VERSION ""

NS_ :

BS_:

BU_: PDCF VDC821 VDC397 HAD3971 PDCM CSC PDCR

BO_ 192 ABS_1: 32 PDCF
 SG_ Checksum_ABS_1 : 0|8@1+ (1,0) [0|255] ""  VDC821,VDC397,HAD3971,PDCM,PDCR
 SG_ WheelSpeed_FL : 8|15@1+ (0.01,0) [0|327.67] "km/h"  VDC821,VDC397,HAD3971,PDCR
 SG_ WheelSpeed_FR : 24|15@1+ (0.01,0) [0|327.67] "km/h"  VDC821,VDC397,HAD3971,PDCR
 SG_ WheelSpeed_RL : 40|15@1+ (0.01,0) [0|327.67] "km/h"  VDC821,VDC397,HAD3971,PDCR
 SG_ WheelSpeed_RR : 56|15@1+ (0.01,0) [0|327.67] "km/h"  VDC821,VDC397,HAD3971,PDCR
 SG_ WheelPulse_FL : 72|8@1+ (1,0) [0|255] ""  VDC821,VDC397,HAD3971,PDCR
 SG_ WheelPulse_FR : 80|8@1+ (1,0) [0|255] ""  VDC821,VDC397,HAD3971,PDCR
 SG_ WheelPulse_RL : 88|8@1+ (1,0) [0|255] ""  VDC821,VDC397,HAD3971,PDCR
 SG_ WheelPulse_RR : 96|8@1+ (1,0) [0|255] ""  VDC821,VDC397,HAD3971,PDCR
 SG_ WheelSpeedDirection_FL : 104|2@1+ (1,0) [0|3] ""  VDC821,VDC397,PDCR
 SG_ WheelSpeedDirection_FR : 106|2@1+ (1,0) [0|3] ""  VDC821,VDC397,PDCR
 SG_ WheelSpeedDirection_RL : 108|2@1+ (1,0) [0|3] ""  VDC821,VDC397,PDCR
 SG_ WheelSpeedDirection_RR : 110|2@1+ (1,0) [0|3] ""  VDC821,VDC397,PDCR
 SG_ WheelSpeedDirection_FL_Q : 112|1@1+ (1,0) [0|1] ""  VDC821,VDC397,PDCR
 SG_ WheelSpeedDirection_FR_Q : 113|1@1+ (1,0) [0|1] ""  VDC821,VDC397,PDCR
 SG_ WheelSpeedDirection_RL_Q : 114|1@1+ (1,0) [0|1] ""  VDC821,VDC397,PDCR
 SG_ WheelSpeedDirection_RR_Q : 115|1@1+ (1,0) [0|1] ""  VDC821,VDC397,PDCR
 SG_ VehicleSpeed : 120|15@1+ (0.01,0) [0|327.67] "km/h"  VDC821,VDC397,HAD3971,PDCM,PDCR
 SG_ VehiclSpeed_Q : 135|1@1+ (1,0) [0|1] ""  VDC821,VDC397,HAD3971,PDCR
 SG_ DrivingDirection : 136|2@1+ (1,0) [0|3] ""  VDC821,VDC397,HAD3971
 SG_ DrivingDirection_Q : 138|1@1+ (1,0) [0|1] ""  VDC821,VDC397,HAD3971
 SG_ BrakeTorqueOnWheels : 152|12@1+ (2,0) [0|8190] "Nm"  VDC821,VDC397
 SG_ EstimatedWheelPressure_FL : 168|14@1+ (0.03125,-50) [-50|450] "bar"  VDC821,VDC397,PDCR
 SG_ EstimatedWheelPressure_FR : 184|14@1+ (0.03125,-50) [-50|450] "bar"  VDC821,VDC397,PDCR
 SG_ EstimatedWheelPressure_RL : 200|14@1+ (0.03125,-50) [-50|450] "bar"  VDC821,VDC397,PDCR
 SG_ EstimatedWheelPressure_RR : 216|14@1+ (0.03125,-50) [-50|450] "bar"  VDC821,VDC397,PDCR
 SG_ LiveCounter_ABS_1 : 252|4@1+ (1,0) [0|15] ""  VDC821,VDC397,HAD3971,PDCM,PDCR

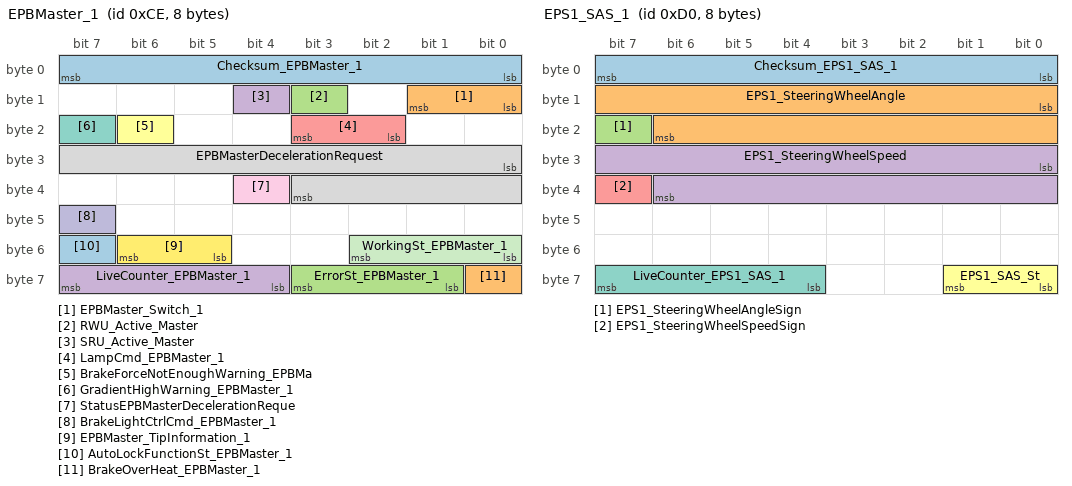
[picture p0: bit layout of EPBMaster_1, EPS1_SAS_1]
BO_ 206 EPBMaster_1: 8 PDCF
 SG_ Checksum_EPBMaster_1 : 0|8@1+ (1,0) [0|255] ""  VDC821,VDC397,HAD3971,PDCM,CSC
 SG_ EPBMaster_Switch_1 : 8|2@1+ (1,0) [0|3] ""  PDCM
 SG_ RWU_Active_Master : 11|1@1+ (1,0) [0|1] ""  PDCM
 SG_ SRU_Active_Master : 12|1@1+ (1,0) [0|1] ""  PDCM
 SG_ LampCmd_EPBMaster_1 : 18|2@1+ (1,0) [0|3] ""  PDCM,CSC
 SG_ BrakeForceNotEnoughWarning_EPBMa : 22|1@1+ (1,0) [0|1] ""  PDCM
 SG_ GradientHighWarning_EPBMaster_1 : 23|1@1+ (1,0) [0|1] ""  PDCM
 SG_ EPBMasterDecelerationRequest : 24|12@1+ (0.01,-20.47) [-20.47|20.48] "m/s2"  PDCM
 SG_ StatusEPBMasterDecelerationReque : 36|1@1+ (1,0) [0|1] ""  PDCM
 SG_ BrakeLightCtrlCmd_EPBMaster_1 : 47|1@1+ (1,0) [0|1] ""  VDC821,VDC397,PDCM
 SG_ WorkingSt_EPBMaster_1 : 48|3@1+ (1,0) [0|7] ""  VDC821,VDC397,HAD3971,PDCM,PDCR,CSC
 SG_ EPBMaster_TipInformation_1 : 53|2@1+ (1,0) [0|3] ""  PDCM
 SG_ AutoLockFunctionSt_EPBMaster_1 : 55|1@1+ (1,0) [0|1] ""  PDCM
 SG_ BrakeOverHeat_EPBMaster_1 : 56|1@1+ (1,0) [0|1] ""  PDCM
 SG_ ErrorSt_EPBMaster_1 : 57|3@1+ (1,0) [0|7] ""  VDC821,VDC397,HAD3971,PDCM
 SG_ LiveCounter_EPBMaster_1 : 60|4@1+ (1,0) [0|15] ""  VDC821,VDC397,PDCM,CSC

BO_ 208 EPS1_SAS_1: 8 PDCF
 SG_ Checksum_EPS1_SAS_1 : 0|8@1+ (1,0) [0|255] ""  VDC821,VDC397,HAD3971,PDCM,PDCR
 SG_ EPS1_SteeringWheelAngle : 8|15@1+ (0.04375,0) [0|1433.55625] "°„"  VDC821,VDC397,HAD3971,PDCM,PDCR
 SG_ EPS1_SteeringWheelAngleSign : 23|1@1+ (1,0) [0|1] ""  VDC821,VDC397,HAD3971,PDCR
 SG_ EPS1_SteeringWheelSpeed : 24|15@1+ (0.04375,0) [0|1433.55625] "°„/s"  VDC821,VDC397,HAD3971,PDCR
 SG_ EPS1_SteeringWheelSpeedSign : 39|1@1+ (1,0) [0|1] ""  VDC821,VDC397,HAD3971,PDCR
 SG_ EPS1_SAS_St : 56|2@1+ (1,0) [0|3] ""  VDC821,VDC397,HAD3971,PDCR
 SG_ LiveCounter_EPS1_SAS_1 : 60|4@1+ (1,0) [0|15] ""  VDC821,VDC397,HAD3971,PDCM,PDCR

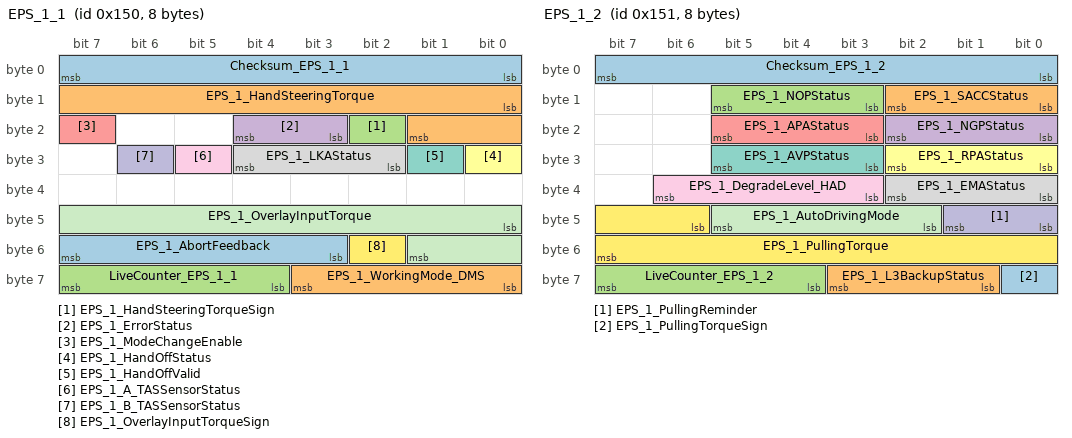
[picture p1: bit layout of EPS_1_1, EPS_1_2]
BO_ 336 EPS_1_1: 8 PDCF
 SG_ Checksum_EPS_1_1 : 0|8@1+ (1,0) [0|255] ""  VDC821,VDC397,HAD3971
 SG_ EPS_1_HandSteeringTorque : 8|10@1+ (0.01,0) [0|10] "Nm"  VDC821,VDC397,HAD3971
 SG_ EPS_1_HandSteeringTorqueSign : 18|1@1+ (1,0) [0|1] ""  VDC821,VDC397,HAD3971
 SG_ EPS_1_ErrorStatus : 19|2@1+ (1,0) [0|3] ""  VDC821,VDC397,HAD3971
 SG_ EPS_1_ModeChangeEnable : 23|1@1+ (1,0) [0|1] ""  VDC821,VDC397
 SG_ EPS_1_HandOffStatus : 24|1@1+ (1,0) [0|1] ""  VDC821,VDC397,HAD3971
 SG_ EPS_1_HandOffValid : 25|1@1+ (1,0) [0|1] ""  VDC821,VDC397,HAD3971
 SG_ EPS_1_LKAStatus : 26|3@1+ (1,0) [0|7] ""  VDC821,VDC397
 SG_ EPS_1_A_TASSensorStatus : 29|1@1+ (1,0) [0|1] ""  VDC821,VDC397
 SG_ EPS_1_B_TASSensorStatus : 30|1@1+ (1,0) [0|1] ""  VDC821,VDC397
 SG_ EPS_1_OverlayInputTorque : 40|10@1+ (0.01,0) [0|10] "Nm"  VDC821,VDC397,HAD3971
 SG_ EPS_1_OverlayInputTorqueSign : 50|1@1+ (1,0) [0|1] ""  VDC821,VDC397,HAD3971
 SG_ EPS_1_AbortFeedback : 51|5@1+ (1,0) [0|31] ""  VDC821,VDC397,HAD3971
 SG_ EPS_1_WorkingMode_DMS : 56|4@1+ (1,0) [0|15] ""  VDC821,VDC397
 SG_ LiveCounter_EPS_1_1 : 60|4@1+ (1,0) [0|15] "Pulse"  VDC821,VDC397

BO_ 337 EPS_1_2: 8 PDCF
 SG_ Checksum_EPS_1_2 : 0|8@1+ (1,0) [0|255] ""  VDC821,VDC397,HAD3971
 SG_ EPS_1_SACCStatus : 8|3@1+ (1,0) [0|7] ""  VDC821,VDC397
 SG_ EPS_1_NOPStatus : 11|3@1+ (1,0) [0|7] ""  VDC821,VDC397,HAD3971
 SG_ EPS_1_NGPStatus : 16|3@1+ (1,0) [0|7] ""  VDC821,VDC397
 SG_ EPS_1_APAStatus : 19|3@1+ (1,0) [0|7] ""  VDC821,VDC397
 SG_ EPS_1_RPAStatus : 24|3@1+ (1,0) [0|7] ""  VDC821,VDC397
 SG_ EPS_1_AVPStatus : 27|3@1+ (1,0) [0|7] ""  VDC821,VDC397
 SG_ EPS_1_EMAStatus : 32|3@1+ (1,0) [0|7] ""  VDC821,VDC397
 SG_ EPS_1_DegradeLevel_HAD : 35|4@1+ (1,0) [0|15] ""  VDC821,VDC397,HAD3971
 SG_ EPS_1_PullingReminder : 40|2@1+ (1,0) [0|3] ""  VDC821,VDC397,HAD3971
 SG_ EPS_1_AutoDrivingMode : 42|4@1+ (1,0) [0|15] ""  VDC821,VDC397,HAD3971
 SG_ EPS_1_PullingTorque : 46|10@1+ (0.01,0) [0|10] "Nm"  VDC821,VDC397,HAD3971
 SG_ EPS_1_PullingTorqueSign : 56|1@1+ (1,0) [0|1] ""  VDC821,VDC397,HAD3971
 SG_ EPS_1_L3BackupStatus : 57|3@1+ (1,0) [0|7] ""  VDC821,VDC397
 SG_ LiveCounter_EPS_1_2 : 60|4@1+ (1,0) [0|15] ""  VDC821,VDC397,HAD3971

BO_ 195 ESC_1_W: 32 PDCF
 SG_ Checksum_ESC_1_W : 0|8@1+ (1,0) [0|255] ""  VDC821,VDC397,PDCR
 SG_ TorqueReductionFast_TCS_FrontWhe : 24|13@1+ (1,0) [0|8000] "Nm"  VDC821,VDC397
 SG_ TorqueIncrease_MSR_FrontWheel : 40|14@1+ (1,-8000) [-8000|8000] "Nm"  VDC821,VDC397
 SG_ TorqueReductionFast_TCS_RearWhee : 72|13@1+ (1,0) [0|8000] "Nm"  VDC821,VDC397
 SG_ TorqueIncrease_MSR_RearWheel : 88|14@1+ (1,-8000) [-8000|8000] "Nm"  VDC821,VDC397
 SG_ ESC_RegenerationTorqueRequest : 104|13@1+ (1,-8000) [-8000|0] "Nm"  VDC821,VDC397
 SG_ ESC_RegenerationTorqueRequest_Q : 134|2@1+ (1,0) [0|3] ""  VDC821,VDC397
 SG_ TorqReductionFastSt_TCS_FrontWhe : 138|1@1+ (1,0) [0|1] ""  VDC821,VDC397
 SG_ TorqueIncreaseSt_MSR_FrontWheel : 140|1@1+ (1,0) [0|1] ""  VDC821,VDC397
 SG_ TorqReductionFastSt_TCS_RearWhee : 146|1@1+ (1,0) [0|1] ""  VDC821,VDC397
 SG_ TorqueIncreaseSt_MSR_RearWheel : 148|1@1+ (1,0) [0|1] ""  VDC821,VDC397,PDCR
 SG_ ESC_StatusRegenerationTorqueRequ : 150|1@1+ (1,0) [0|1] ""  VDC821,VDC397
 SG_ ESC_FrontBiasMax : 152|7@1+ (1,0) [0|100] "%"  VDC821,VDC397
 SG_ ESC_RearBiasMax : 160|7@1+ (1,0) [0|100] "%"  VDC821,VDC397
 SG_ LiveCounter_ESC_1_W : 252|4@1+ (1,0) [0|15] ""  VDC821,VDC397,PDCR

BO_ 306 ESC_2_1: 24 PDCF
 SG_ Checksum_ESC_2_1 : 0|8@1+ (1,0) [0|255] ""  VDC821,VDC397,PDCM,PDCR,CSC
 SG_ WorkingSt_ESC : 8|1@1+ (1,0) [0|1] ""  VDC821,VDC397,HAD3971,PDCM,PDCR
 SG_ ErrorSt_ESC : 9|1@1+ (1,0) [0|1] ""  VDC821,VDC397,HAD3971,PDCM,PDCR
 SG_ Intervention_ESC : 10|1@1+ (1,0) [0|1] ""  VDC821,VDC397,HAD3971,PDCM,PDCR
 SG_ ErrorSt_ABS : 11|1@1+ (1,0) [0|1] ""  VDC821,VDC397,HAD3971,PDCM,PDCR,CSC
 SG_ Intervention_ABS : 12|1@1+ (1,0) [0|1] ""  VDC821,VDC397,HAD3971,PDCM,PDCR
 SG_ ESC_Status_RollerBenchMode : 13|1@1+ (1,0) [0|1] ""  VDC821,VDC397
 SG_ Intervention_TCS : 14|1@1+ (1,0) [0|1] ""  VDC821,VDC397,HAD3971,PDCM,PDCR
 SG_ ErrorSt_EBD : 15|1@1+ (1,0) [0|1] ""  VDC821,VDC397,PDCM,PDCR,CSC
 SG_ AvailableSt_CDP : 16|1@1+ (1,0) [0|1] ""  VDC821,VDC397,HAD3971,PDCR
 SG_ Intervention_CDP : 17|1@1+ (1,0) [0|1] ""  VDC821,VDC397,HAD3971
 SG_ AvailableSt_HHC : 24|1@1+ (1,0) [0|1] ""  VDC821,VDC397
 SG_ Intervention_HHC : 25|1@1+ (1,0) [0|1] ""  VDC821,VDC397
 SG_ AvailableSt_HDC : 26|1@1+ (1,0) [0|1] ""  VDC821,VDC397,HAD3971
 SG_ WorkingSt_HDC : 27|2@1+ (1,0) [0|3] ""  VDC821,VDC397,HAD3971
 SG_ ErrorSt_AVH : 29|1@1+ (1,0) [0|1] ""  VDC821,VDC397,HAD3971
 SG_ WorkingSt_AVH : 30|2@1+ (1,0) [0|3] ""  VDC821,VDC397,HAD3971,PDCR
 SG_ AvailableSt_AEB : 34|1@1+ (1,0) [0|1] ""  VDC821,VDC397
 SG_ Intervention_AEB : 35|1@1+ (1,0) [0|1] ""  VDC821,VDC397,PDCM
 SG_ AvailableSt_ABP : 36|1@1+ (1,0) [0|1] ""  VDC821,VDC397
 SG_ Intervention_ABP : 37|1@1+ (1,0) [0|1] ""  VDC821,VDC397
 SG_ AvailableSt_AWB : 38|1@1+ (1,0) [0|1] ""  VDC821,VDC397
 SG_ Intervention_AWB : 39|1@1+ (1,0) [0|1] ""  VDC821,VDC397
 SG_ AvailableSt_HBA : 40|1@1+ (1,0) [0|1] ""  VDC821,VDC397
 SG_ Intervention_HBA : 41|1@1+ (1,0) [0|1] ""  VDC821,VDC397
 SG_ Intervention_EmergencyBrake : 45|1@1+ (1,0) [0|1] ""  VDC821,VDC397
 SG_ VehicleStandstillSt_ESC : 46|1@1+ (1,0) [0|1] ""  VDC821,VDC397,HAD3971
 SG_ BrakeLightCtrlCmd_ESC : 47|1@1+ (1,0) [0|1] ""  VDC821,VDC397
 SG_ Intervention_BTCS_F : 50|1@1+ (1,0) [0|1] ""  VDC821,VDC397
 SG_ Intervention_BTCS_R : 51|1@1+ (1,0) [0|1] ""  VDC821,VDC397
 SG_ AvailableSt_MSR : 52|1@1+ (1,0) [0|1] ""  VDC821,VDC397
 SG_ RoughRoadLevel : 57|3@1+ (1,0) [0|7] ""  VDC821,VDC397,PDCM
 SG_ BrakeHoldActive : 60|1@1+ (1,0) [0|1] ""  VDC821,VDC397
 SG_ ParkingRequestToEPB : 62|2@1+ (1,0) [0|3] ""  VDC821,VDC397,PDCR
 SG_ WorkingMode_ESC : 64|4@1+ (1,0) [0|15] ""  VDC821,VDC397
 SG_ ModeChangeEnable_ESC : 69|1@1+ (1,0) [0|1] ""  VDC821,VDC397
 SG_ WorkingSt_CST : 72|2@1+ (1,0) [0|3] ""  VDC821,VDC397
 SG_ LiveCounter_ESC_2_1 : 188|4@1+ (1,0) [0|15] ""  VDC821,VDC397,PDCM,PDCR,CSC

BO_ 312 ESC_5_1: 24 PDCF
 SG_ Checksum_ESC_5_1 : 0|8@1+ (1,0) [0|255] ""  VDC821,VDC397,HAD3971
 SG_ ESC_TorqueReq_VMC_1 : 8|17@1+ (0.25,-13000) [-13000|13000] "Nm"  VDC821,VDC397
 SG_ ESC_TorqueReqSt_VMC_1 : 28|2@1+ (1,0) [0|3] ""  VDC821,VDC397
 SG_ ESC_TargetGearReq_VMC_1 : 32|3@1+ (1,0) [0|7] ""  VDC821,VDC397
 SG_ ESC_TargetGearReqEnable_VMC_1 : 35|1@1+ (1,0) [0|1] ""  VDC821,VDC397
 SG_ ESC_SuspendStatus_L2 : 36|3@1+ (1,0) [0|7] ""  VDC821,VDC397
 SG_ ESC_EPBAvailableSt_L3 : 39|1@1+ (1,0) [0|1] ""  VDC821,VDC397,HAD3971
 SG_ ESC_CommunicationSt_L3 : 40|1@1+ (1,0) [0|1] ""  VDC821,VDC397,HAD3971
 SG_ ESC_UsedChannel_L3 : 41|2@1+ (1,0) [0|3] ""  VDC821,VDC397,HAD3971
 SG_ ESC_ControllerReleaseSt_L3 : 43|1@1+ (1,0) [0|1] ""  VDC821,VDC397,HAD3971
 SG_ ESC_SuspendStatusByDriver_L3 : 44|2@1+ (1,0) [0|3] ""  VDC821,VDC397,HAD3971
 SG_ ESC_SuspendStatusByOther_L3 : 46|1@1+ (1,0) [0|1] ""  VDC821,VDC397,HAD3971
 SG_ ESC_VLC_Error_L12 : 50|2@1+ (1,0) [0|3] ""  VDC821,VDC397
 SG_ ESC_VLCSt : 52|2@1+ (1,0) [0|3] ""  VDC821,VDC397,HAD3971
 SG_ ESC_VMC_Error_L3 : 54|3@1+ (1,0) [0|7] ""  VDC821,VDC397,HAD3971
 SG_ ESC_AutoDriving_LC_Brakemode : 57|2@1+ (1,0) [0|3] ""  VDC821,VDC397
 SG_ ESC_AutoPark_LC_HPA_Avail : 59|2@1+ (1,0) [0|3] ""  VDC821,VDC397
 SG_ ESC_AutoPark_LCSt : 72|3@1+ (1,0) [0|7] ""  VDC821,VDC397
 SG_ ESC_AutoPark_LC_APA_Avail : 76|2@1+ (1,0) [0|3] ""  VDC821,VDC397
 SG_ ESC_AutoPark_LC_RPA_Avail : 80|2@1+ (1,0) [0|3] ""  VDC821,VDC397
 SG_ ESC_AutoPark_LC_AVP_Avail : 84|2@1+ (1,0) [0|3] ""  VDC821,VDC397
 SG_ ESC_AutoPark_LCFailureSt : 88|4@1+ (1,0) [0|15] ""  VDC821,VDC397
 SG_ ESC_AutoPark_LC_BrakeMode : 92|2@1+ (1,0) [0|3] ""  VDC821,VDC397
 SG_ ESC_HDCActiveForbidden : 104|1@1+ (1,0) [0|1] ""  VDC821,VDC397
 SG_ ESC_ESCOffForbidden : 105|1@1+ (1,0) [0|1] ""  VDC821,VDC397
 SG_ ESC_AVHActiveForbidden : 106|1@1+ (1,0) [0|1] ""  VDC821,VDC397
 SG_ ESC_ShutOffFinished : 107|1@1+ (1,0) [0|1] ""  VDC821,VDC397
 SG_ ESC_BrakePadelOverride : 108|1@1+ (1,0) [0|1] ""  VDC821,VDC397
 SG_ LiveCounter_ESC_5_1 : 188|4@1+ (1,0) [0|15] "Pulse"  VDC821,VDC397,HAD3971

BO_ 193 IBC_1: 32 PDCF
 SG_ Checksum_IBC_1 : 0|8@1+ (1,0) [0|255] ""  VDC821,VDC397,HAD3971,PDCR
 SG_ IBC_SimulatorPressure : 8|10@1+ (0.3,-5) [-5|301.9] "bar"  VDC821,VDC397,HAD3971
 SG_ IBC_SimulatorPressureSt : 18|1@1+ (1,0) [0|1] ""  VDC821,VDC397,HAD3971
 SG_ IBC_SystemStatus : 19|3@1+ (1,0) [0|7] ""  VDC821,VDC397
 SG_ IBC_PlungerPressure : 24|10@1+ (0.3,-5) [-5|301.9] "bar"  VDC821,VDC397,HAD3971,PDCR
 SG_ IBC_PlungerPressureSt : 34|1@1+ (1,0) [0|1] ""  VDC821,VDC397,HAD3971,PDCR
 SG_ IBC_BrakePedalStatus_Q : 38|2@1+ (1,0) [0|3] ""  VDC821,VDC397,HAD3971
 SG_ IBC_InputRodStroke : 40|10@1+ (0.05,-5) [-5|46.15] "mm"  VDC821,VDC397,HAD3971
 SG_ IBC_InputRodStrokeSt : 50|1@1+ (1,0) [0|1] ""  VDC821,VDC397,HAD3971
 SG_ IBC_BrakeFluidWarning : 51|2@1+ (1,0) [0|3] ""  VDC821,VDC397
 SG_ IBC_BrakePedalStatus : 53|2@1+ (1,0) [0|3] ""  VDC821,VDC397,HAD3971
 SG_ TwoFootBrakeSt : 57|1@1+ (1,0) [0|1] ""  VDC821,VDC397
 SG_ DegradedBBFWarning : 58|1@1+ (1,0) [0|1] ""  VDC821,VDC397
 SG_ IBC_MILInfo : 59|1@1+ (1,0) [0|1] "" Vector__XXX
 SG_ FWAWarning : 60|2@1+ (1,0) [0|3] ""  VDC821,VDC397
 SG_ IBC_RearWheelAngleRequest : 64|12@1+ (0.01,-20.48) [-20.48|20.47] "°„"  VDC821,VDC397
 SG_ IBC_RearWheelAngleRequestSt : 76|1@1+ (1,0) [0|1] ""  VDC821,VDC397
 SG_ IBC_VDCActive : 77|1@1+ (1,0) [0|1] ""  VDC821,VDC397
 SG_ LiveCounter_IBC_1 : 252|4@1+ (1,0) [0|15] ""  VDC821,VDC397,HAD3971,PDCR

BO_ 1381 IBC_SlaveFVReq: 8 PDCF
 SG_ SECOC_FVReqCode_IBC : 0|8@1+ (1,0) [0|0] ""  VDC397

BO_ 554 LampFL_1: 8 PDCF
 SG_ LimphomeSt_FL : 0|1@1+ (1,0) [0|1] ""  VDC821
 SG_ PositionLightSt_FL : 1|1@1+ (1,0) [0|1] ""  VDC821
 SG_ DayRunningLightSt_FL : 4|1@1+ (1,0) [0|1] ""  VDC821
 SG_ FogLightSt_FL : 10|1@1+ (1,0) [0|1] ""  VDC821
 SG_ TurningSt_FL : 12|1@1+ (1,0) [0|1] ""  VDC821
 SG_ TurningSt_LeftSide : 14|1@1+ (1,0) [0|1] ""  VDC821
 SG_ ADSLightSt_FL : 15|1@1+ (1,0) [0|1] ""  VDC821
 SG_ CeremonyModeStatus_FL : 16|3@1+ (1,0) [0|7] ""  VDC821
 SG_ TurnLightFaultSt_LeftSide : 19|1@1+ (1,0) [0|1] ""  VDC821
 SG_ HighBeamSt_FL : 22|1@1+ (1,0) [0|1] ""  VDC821
 SG_ FoglightFaultSt_FL : 24|1@1+ (1,0) [0|1] ""  VDC821
 SG_ HighbeamFaultSt_FL : 26|1@1+ (1,0) [0|1] ""  VDC821
 SG_ PositionLightFaultSt_FL : 27|1@1+ (1,0) [0|1] ""  VDC821
 SG_ DayRunningLightFaultSt_FL : 28|1@1+ (1,0) [0|1] ""  VDC821
 SG_ TurningLightFaultSt_FL : 29|1@1+ (1,0) [0|1] ""  VDC821
 SG_ ADSLightFaultSt_FL : 31|1@1+ (1,0) [0|1] ""  VDC821
 SG_ CornerLampSt_FL : 34|1@1+ (1,0) [0|1] ""  VDC821
 SG_ LampOTAMode_FL : 41|1@1+ (1,0) [0|1] ""  VDC821
 SG_ CornerLampFaultSt_FL : 42|1@1+ (1,0) [0|1] ""  VDC821
 SG_ ALS_Init_FL : 43|2@1+ (1,0) [0|3] ""  VDC821
 SG_ ALS_MotorFault_FL : 45|3@1+ (1,0) [0|7] ""  VDC821
 SG_ ALS_MotorPosition_FL : 48|16@1+ (0.0001,0) [0|6.5535] ""  VDC821

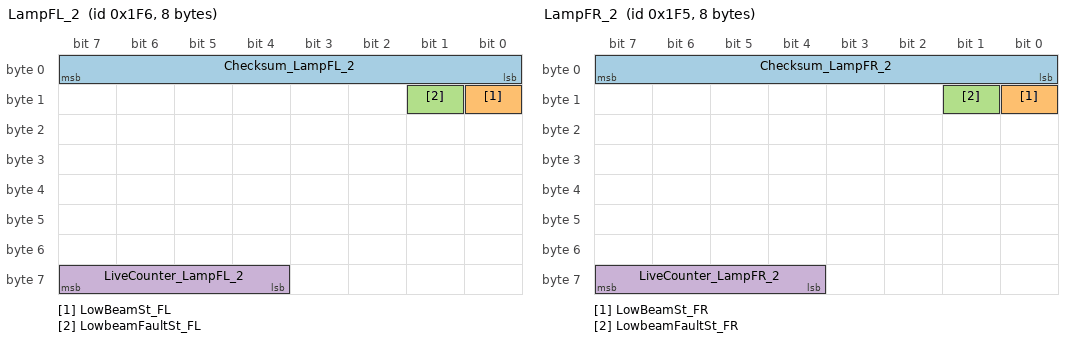
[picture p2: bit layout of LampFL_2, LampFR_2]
BO_ 502 LampFL_2: 8 PDCF
 SG_ Checksum_LampFL_2 : 0|8@1+ (1,0) [0|255] ""  VDC821
 SG_ LowBeamSt_FL : 8|1@1+ (1,0) [0|1] ""  VDC821
 SG_ LowbeamFaultSt_FL : 9|1@1+ (1,0) [0|1] ""  VDC821
 SG_ LiveCounter_LampFL_2 : 60|4@1+ (1,0) [0|15] "pulse"  VDC821

BO_ 810 LampFR_1: 8 PDCF
 SG_ LimphomeSt_FR : 0|1@1+ (1,0) [0|1] ""  VDC821
 SG_ PositionLightSt_FR : 1|1@1+ (1,0) [0|1] ""  VDC821
 SG_ DayRunningLightSt_FR : 4|1@1+ (1,0) [0|1] ""  VDC821
 SG_ FogLightSt_FR : 10|1@1+ (1,0) [0|1] ""  VDC821
 SG_ TurningSt_FR : 12|1@1+ (1,0) [0|1] ""  VDC821
 SG_ TurningSt_RightSide : 14|1@1+ (1,0) [0|1] ""  VDC821
 SG_ ADSLightSt_FR : 15|1@1+ (1,0) [0|1] ""  VDC821
 SG_ CeremonyModeStatus_FR : 16|3@1+ (1,0) [0|7] ""  VDC821
 SG_ TurnLightFaultSt_RightSide : 19|1@1+ (1,0) [0|1] ""  VDC821
 SG_ HighBeamSt_FR : 22|1@1+ (1,0) [0|1] ""  VDC821
 SG_ FoglightFaultSt_FR : 24|1@1+ (1,0) [0|1] ""  VDC821
 SG_ HighbeamFaultSt_FR : 26|1@1+ (1,0) [0|1] ""  VDC821
 SG_ PositionLightFaultSt_FR : 27|1@1+ (1,0) [0|1] ""  VDC821
 SG_ DayRunningLightFaultSt_FR : 28|1@1+ (1,0) [0|1] ""  VDC821
 SG_ TurningLightFaultSt_FR : 29|1@1+ (1,0) [0|1] ""  VDC821
 SG_ ADSLightFaultSt_FR : 31|1@1+ (1,0) [0|1] ""  VDC821
 SG_ CornerLampSt_FR : 34|1@1+ (1,0) [0|1] ""  VDC821
 SG_ LampOTAMode_FR : 41|1@1+ (1,0) [0|1] ""  VDC821
 SG_ CornerLampFaultSt_FR : 42|1@1+ (1,0) [0|1] ""  VDC821
 SG_ ALS_Init_FR : 43|2@1+ (1,0) [0|3] ""  VDC821
 SG_ ALS_MotorFault_FR : 45|3@1+ (1,0) [0|7] ""  VDC821
 SG_ ALS_MotorPosition_FR : 48|16@1+ (0.0001,0) [0|6.5535] ""  VDC821

BO_ 501 LampFR_2: 8 PDCF
 SG_ Checksum_LampFR_2 : 0|8@1+ (1,0) [0|255] ""  VDC821
 SG_ LowBeamSt_FR : 8|1@1+ (1,0) [0|1] ""  VDC821
 SG_ LowbeamFaultSt_FR : 9|1@1+ (1,0) [0|1] ""  VDC821
 SG_ LiveCounter_LampFR_2 : 60|4@1+ (1,0) [0|15] "pulse"  VDC821

BO_ 1210 OTA_VersionEPS: 8 PDCF
 SG_ SoftwareNumber_EPS : 0|24@1+ (1,0) [0|0] ""  VDC821
 SG_ HardwareRelated_ConfigID_EPS : 24|16@1+ (1,0) [0|0] ""  VDC821

BO_ 1260 OTA_VersionIBC: 8 PDCF
 SG_ SoftwareNumber_IBC : 0|24@1+ (1,0) [0|0] ""  VDC821
 SG_ HardwareRelated_ConfigID_IBC : 24|16@1+ (1,0) [0|0] ""  VDC821

BO_ 1272 OTA_VersionMCUF: 8 PDCF
 SG_ SoftwareNumber_MCUF : 0|24@1+ (1,0) [0|0] ""  VDC821
 SG_ HardwareRelated_ConfigID_MCUF : 24|16@1+ (1,0) [0|0] ""  VDC821

BO_ 1193 OTA_VersionPDCF: 8 PDCF
 SG_ SoftwareNumber_PDCF : 0|24@1+ (1,0) [0|0] ""  VDC821
 SG_ HardwareRelated_ConfigID_PDCF : 24|16@1+ (1,0) [0|0] ""  VDC821

BO_ 1065 OTA_VersionPDCM: 8 PDCF
 SG_ SoftwareNumber_PDCM : 0|24@1+ (1,0) [0|0] ""  VDC821
 SG_ HardwareRelated_ConfigID_PDCM : 24|16@1+ (1,0) [0|0] ""  VDC821

BO_ 1199 OTA_VersionRBU: 8 PDCF
 SG_ SoftwareNumber_RBU : 0|24@1+ (1,0) [0|0] ""  VDC821
 SG_ HardwareRelated_ConfigID_RBU : 24|16@1+ (1,0) [0|0] ""  VDC821

BO_ 1214 OTA_VersionRWS: 8 PDCF
 SG_ SoftwareNumber_RWS : 0|24@1+ (1,0) [0|0] ""  VDC821
 SG_ HardwareRelated_ConfigID_RWS : 24|16@1+ (1,0) [0|0] ""  VDC821

BO_ 1037 OTA_versionLAMP_FL: 8 PDCF
 SG_ SoftwareNumber_LAMP_FL : 0|24@1+ (1,0) [0|0] ""  VDC821
 SG_ HardwareRelated_ConfigID_LAMP_FL : 24|16@1+ (1,0) [0|0] ""  VDC821

BO_ 1211 OTA_versionLAMP_FR: 8 PDCF
 SG_ SoftwareNumber_LAMP_FR : 0|24@1+ (1,0) [0|0] ""  VDC821
 SG_ HardwareRelated_ConfigID_LAMP_FR : 24|16@1+ (1,0) [0|0] ""  VDC821

BO_ 1215 OTA_versionPNG1: 8 PDCF
 SG_ SoftwareNumber_PNG1 : 0|24@1+ (1,0) [0|0] ""  VDC821
 SG_ HardwareRelated_ConfigID_PNG1 : 24|16@1+ (1,0) [0|0] ""  VDC821

BO_ 1276 OTA_versionPNG2: 8 PDCF
 SG_ SoftwareNumber_PNG2 : 0|24@1+ (1,0) [0|0] ""  VDC821
 SG_ HardwareRelated_ConfigID_PNG2 : 24|16@1+ (1,0) [0|0] ""  VDC821

BO_ 1377 PDCF_SlaveFVReq: 8 PDCF
 SG_ SECOC_FVReqCode_PDCF : 0|8@1+ (1,0) [0|0] ""  VDC397

CM_ SG_ 192 Checksum_ABS_1 "The checksum is used to check whether the data from the CPU buffer are shifted without transmission errors to the CAN communication controller buffer and vice versa.";
CM_ SG_ 192 WheelSpeed_FL "This signal is front left wheel speed which sent by ABS with filtering. ";
CM_ SG_ 192 WheelSpeed_FR "This signal is front right wheel speed which sent by ABS with filtering.";
CM_ SG_ 192 WheelSpeed_RL "This signal is rear left wheel speed which sent by ABS with filtering.";
CM_ SG_ 192 WheelSpeed_RR "This signal is rear right wheel speed which sent by ABS with filtering.";
CM_ SG_ 192 WheelPulse_FL "This signal is the front left wheel speed pulse(raw data,without filtering,without compensated).";
CM_ SG_ 192 WheelPulse_FR "This signal is the front right wheel speed pulse(raw data,without filtering,without compensated).";
CM_ SG_ 192 WheelPulse_RL "This signal is the rear left wheel speed pulse(raw data,without filtering,without compensated).";
CM_ SG_ 192 WheelPulse_RR "This signal is the rear right wheel speed pulse(raw data,without filtering,without compensated).";
CM_ SG_ 192 WheelSpeedDirection_FL "This signal is the the front left wheel speed direction.";
CM_ SG_ 192 WheelSpeedDirection_FR "This signal is the the front right wheel speed direction.";
CM_ SG_ 192 WheelSpeedDirection_RL "This signal is the the rear left wheel speed direction.";
CM_ SG_ 192 WheelSpeedDirection_RR "This signal is the the rear right  wheel speed direction.";
CM_ SG_ 192 WheelSpeedDirection_FL_Q "Qualifier for WheelSpeedDirection_FL.";
CM_ SG_ 192 WheelSpeedDirection_FR_Q "Qualifier for WheelSpeedDirection_FR.";
CM_ SG_ 192 WheelSpeedDirection_RL_Q "Qualifier for WheelSpeedDirection_RL.";
CM_ SG_ 192 WheelSpeedDirection_RR_Q "Qualifier for WheelSpeedDirection_RR.";
CM_ SG_ 192 VehicleSpeed "The signal describes the raw vehicle speed calculated by ABS. The ABS calculates the vehicle speed based on the raw wheel speed signals from the wheel speed sensors. The vehicle speed output could be the average of the wheel speeds of the driven axle.";
CM_ SG_ 192 VehiclSpeed_Q "Qualifier for VehicleSpeed";
CM_ SG_ 192 DrivingDirection "The signal indicates driving direction of the vehicle.";
CM_ SG_ 192 DrivingDirection_Q "Qualifier for DrivingDirection";
CM_ SG_ 192 BrakeTorqueOnWheels "This signal is the total hydraulic bake torque on 4 wheels(Except EPB etc.).If current brake torque is over 8188Nm,it will always send the max value 8188 Nm.";
CM_ SG_ 192 EstimatedWheelPressure_FL "The signal indicates the estimated or modeled wheel pressure of the respective wheel brake of front left.";
CM_ SG_ 192 EstimatedWheelPressure_FR "The signal indicates the estimated or modeled wheel pressure of the respective wheel brake of front right.";
CM_ SG_ 192 EstimatedWheelPressure_RL "The signal indicates the estimated or modeled wheel pressure of the respective wheel brake of rear left.";
CM_ SG_ 192 EstimatedWheelPressure_RR "The signal indicates the estimated or modeled wheel pressure of the respective wheel brake of rear left.";
CM_ SG_ 192 LiveCounter_ABS_1 "The Livecounter is used to check the signal consistency of the messages . If the signals are consecutive, the LiveCounter should also be sequential in the way 0, 1, 2 ...X(depends on E2E usage), 0, 1 °≠";
CM_ SG_ 206 Checksum_EPBMaster_1 "The checksum is used to check whether the data from the CPU buffer are shifted without transmission errors to the CAN communication controller buffer and vice versa.";
CM_ SG_ 206 EPBMaster_Switch_1 "This signal indicates if the switch of EPB";
CM_ SG_ 206 RWU_Active_Master "Indicates if the RWU is active or not.";
CM_ SG_ 206 SRU_Active_Master "Indicates if the SRU is active or not.";
CM_ SG_ 206 LampCmd_EPBMaster_1 "The signal indicates the lamp indication of EPB.";
CM_ SG_ 206 BrakeForceNotEnoughWarning_EPBMa "This signal is warning command for EPB warning.
Indicates the brake force not enough";
CM_ SG_ 206 GradientHighWarning_EPBMaster_1 "This signal is warning command for EPB warning.
Indicates the gradient is too high ";
CM_ SG_ 206 EPBMasterDecelerationRequest "EPB deceleration request for wheel brake";
CM_ SG_ 206 StatusEPBMasterDecelerationReque "Status of the deceleration request from EPB in case of no request  EPBDecelerationRequest=0xFFE.";
CM_ SG_ 206 BrakeLightCtrlCmd_EPBMaster_1 "The signal indicates the brake light control command.";
CM_ SG_ 206 WorkingSt_EPBMaster_1 "The signal indicates the working status of EPB.";
CM_ SG_ 206 EPBMaster_TipInformation_1 "Tip to inform the driver how to do the next step";
CM_ SG_ 206 AutoLockFunctionSt_EPBMaster_1 "This signal indicates EPB auto lock function status
";
CM_ SG_ 206 BrakeOverHeat_EPBMaster_1 "This signal indicates brake block temperature is high or not
";
CM_ SG_ 206 ErrorSt_EPBMaster_1 "The signal indicates the working status of EPB master node.";
CM_ SG_ 206 LiveCounter_EPBMaster_1 "The Livecounter is used to check the signal consistency of the messages . If the signals are consecutive, the LiveCounter should also be sequential in the way 0, 1, 2 ...X(depends on E2E usage), 0, 1 °≠";
CM_ SG_ 208 Checksum_EPS1_SAS_1 "The checksum is used to check whether the data from the CPU buffer are shifted without transmission errors to the CAN communication controller buffer and vice versa.";
CM_ SG_ 208 EPS1_SteeringWheelAngle "This signal indicates the angle of steering wheel .";
CM_ SG_ 208 EPS1_SteeringWheelAngleSign "This signal shows the direction of steering wheel angle, it's used in pairs with °∞SteeringWheelAngle°±.";
CM_ SG_ 208 EPS1_SteeringWheelSpeed "This signal indicates the teering wheel rotation speed.";
CM_ SG_ 208 EPS1_SteeringWheelSpeedSign "This signal shows the direction of steering wheel speed, it's used in pairs with °∞SteeringWheelSpeed°±. ";
CM_ SG_ 208 EPS1_SAS_St "The signal indicates the status of SAS. ";
CM_ SG_ 208 LiveCounter_EPS1_SAS_1 "The Livecounter is used to check the signal consistency of the messages . If the signals are consecutive, the LiveCounter should also be sequential in the way 0, 1, 2 ...X(depends on E2E usage), 0, 1 °≠";
CM_ SG_ 336 EPS_1_HandSteeringTorque "The signal indicates the torque measured by the torque sensor at the steering wheel. In case of a sensor error, the default value (0x3FF) of the signal is set";
CM_ SG_ 336 EPS_1_HandSteeringTorqueSign "Indicates sign of hand steering torque (+/-)
Hand steering torque to left = positive
Hand steering torque to right = negative
";
CM_ SG_ 336 EPS_1_ErrorStatus "Error indication of the EPS system";
CM_ SG_ 336 EPS_1_ModeChangeEnable "Indicates whether EPS can change the working mode in the current condition";
CM_ SG_ 336 EPS_1_HandOffStatus "Detect if the driver is controlling the steering wheel";
CM_ SG_ 336 EPS_1_HandOffValid "Indicates if the hand off signal is valid or not.";
CM_ SG_ 336 EPS_1_LKAStatus "The signal indicates the status of LDP(LKA) function ";
CM_ SG_ 336 EPS_1_A_TASSensorStatus "The signal indicates the status of torque sensor.";
CM_ SG_ 336 EPS_1_B_TASSensorStatus "The signal indicates the status of torque sensor.";
CM_ SG_ 336 EPS_1_OverlayInputTorque "The signal indicates the actual applied overlay toque in EPS.";
CM_ SG_ 336 EPS_1_OverlayInputTorqueSign "Indicates sign of OverlayInputTorque (+/-)
Hand steering torque to left = positive
Hand steering torque to right = negative
";
CM_ SG_ 336 EPS_1_AbortFeedback "EPS APC/L2/L3 Abort Feedback";
CM_ SG_ 336 EPS_1_WorkingMode_DMS "Indicates the current working mode of EPS as the feedback to the  command of Drive Mode Selection ECU";
CM_ SG_ 337 Checksum_EPS_1_2 "The checksum is used to check whether the data from the CPU buffer are shifted without transmission errors to the CAN communication controller buffer and vice versa.";
CM_ SG_ 337 EPS_1_SACCStatus "The signal indicates the status of SACC/LCA/HWA/TJA function ";
CM_ SG_ 337 EPS_1_NOPStatus "The signal indicates the status of NOP function ";
CM_ SG_ 337 EPS_1_NGPStatus "The signal indicates the status of NGP function ";
CM_ SG_ 337 EPS_1_APAStatus "The signal indicates the status of APA function ";
CM_ SG_ 337 EPS_1_RPAStatus "The signal indicates the status of RPA function ";
CM_ SG_ 337 EPS_1_AVPStatus "The signal indicates the status of AVP function ";
CM_ SG_ 337 EPS_1_EMAStatus "The signal indicates the status of EMA function ";
CM_ SG_ 337 EPS_1_DegradeLevel_HAD "EPS capability description under different faults for autonomous Driving";
CM_ SG_ 337 EPS_1_PullingReminder "Indicates the EPS pulling status.";
CM_ SG_ 337 EPS_1_AutoDrivingMode "Which auto driving/parking mode is active";
CM_ SG_ 337 EPS_1_PullingTorque "The signal indicates the Pulling torque in EPS.";
CM_ SG_ 337 EPS_1_PullingTorqueSign "Indicates sign of PullingTorque (+/-)
PullingTorque to left = positive
PullingTorque to right = negative
";
CM_ SG_ 337 EPS_1_L3BackupStatus "The signal indicates the status of L3Backup function";
CM_ SG_ 337 LiveCounter_EPS_1_2 "The Livecounter is used to check the signal consistency of the messages . If the signals are consecutive, the LiveCounter should also be sequential in the way 0, 1, 2 ...X(depends on E2E usage), 0, 1 °≠";
CM_ SG_ 195 Checksum_ESC_1_W "The checksum is used to check whether the data from the CPU buffer are shifted without transmission errors to the CAN communication controller buffer and vice versa.";
CM_ SG_ 195 TorqueReductionFast_TCS_FrontWhe "The signal describes a fast torque reduction request (inner torque level) from TCS, realized by air reduction via throttle position adjustment. The request for fast torque reduction is sent in the driving torque control mode (AMR). In case of no torque request: TorqueReductionFast_TCS = 0x1FFE. In case of an error, the error value 0x1FFF is sent.,the torque is  wheel torque.";
CM_ SG_ 195 TorqueIncrease_MSR_FrontWheel "The signal describes the torque increase request (inner torque level) from MSR. In case of no torque request: TorqueIncrease_MSR = 0x3FFE. In case of an error, the error value 0x3FFF is sent,the torque is  wheel torque.";
CM_ SG_ 195 TorqueReductionFast_TCS_RearWhee "The signal describes a fast torque reduction request (inner torque level) from TCS, realized by air reduction via throttle position adjustment. The request for fast torque reduction is sent in the driving torque control mode (AMR). In case of no torque request: TorqueReductionFast_TCS = 0x1FFE. In case of an error, the error value 0x1FFF is sent.,the torque is  wheel torque.";
CM_ SG_ 195 TorqueIncrease_MSR_RearWheel "The signal describes the torque increase request (inner torque level) from MSR. In case of no torque request: TorqueIncrease_MSR = 0x3FFE. In case of an error, the error value 0x3FFF is sent,the torque is  wheel torque.";
CM_ SG_ 195 ESC_RegenerationTorqueRequest "RegenerationTorqueRequest,the torque is  wheel torque.
Recovery torque, HCU to be treated as negative";
CM_ SG_ 195 ESC_RegenerationTorqueRequest_Q "The quality of signal ESC_RegenerationTorqueRequest";
CM_ SG_ 195 TorqReductionFastSt_TCS_FrontWhe "This signal indicates the status of torque fast reduction request from TCS.";
CM_ SG_ 195 TorqueIncreaseSt_MSR_FrontWheel "This signal indicates the status of troque increase request from MSR.";
CM_ SG_ 195 TorqReductionFastSt_TCS_RearWhee "This signal indicates the status of torque fast reduction request from TCS.";
CM_ SG_ 195 TorqueIncreaseSt_MSR_RearWheel "This signal indicates the status of troque increase request from MSR.";
CM_ SG_ 195 ESC_StatusRegenerationTorqueRequ "status of regneration torque request";
CM_ SG_ 195 ESC_FrontBiasMax "The maximum bias of front axle for brake regeneration.";
CM_ SG_ 195 ESC_RearBiasMax "The maximum bias of rear axle for brake regeneration.";
CM_ SG_ 195 LiveCounter_ESC_1_W "The Livecounter is used to check the signal consistency of the messages . If the signals are consecutive, the LiveCounter should also be sequential in the way 0, 1, 2 ...X(depends on E2E usage), 0, 1 °≠";
CM_ SG_ 306 Checksum_ESC_2_1 "The checksum is used to check whether the data from the CPU buffer are shifted without transmission errors to the CAN communication controller buffer and vice versa.";
CM_ SG_ 306 WorkingSt_ESC "This signal indicates the ESC system working status.";
CM_ SG_ 306 ErrorSt_ESC "This signal indicates the ESC function error status,including VDC and TCS.";
CM_ SG_ 306 Intervention_ESC "The signal is indicates if the ESC function is intervention or not.";
CM_ SG_ 306 ErrorSt_ABS "This signal indicates the ABS function error status.";
CM_ SG_ 306 Intervention_ABS "The signal indicates if the ABS function is intervention or not.";
CM_ SG_ 306 ESC_Status_RollerBenchMode "The signal indicates the status of roller bench mode.";
CM_ SG_ 306 Intervention_TCS "The signal indicates if the TCS function is intervention or not.";
CM_ SG_ 306 ErrorSt_EBD "This signal indicates the EBD function error status.";
CM_ SG_ 306 AvailableSt_CDP "This signal Indicates if the CDP function is available or not";
CM_ SG_ 306 Intervention_CDP "The signal is indicates if the CDP function is intervention or not.";
CM_ SG_ 306 AvailableSt_HHC "This signal indicates if the HHC function is available or not";
CM_ SG_ 306 Intervention_HHC "The signal is indicates if the HHC function is intervention or not.";
CM_ SG_ 306 AvailableSt_HDC "This signal indicates if the HDC function is available or not";
CM_ SG_ 306 WorkingSt_HDC "The signal indicates the working status of HDC.";
CM_ SG_ 306 ErrorSt_AVH "This signal indicates if the AVH function is error or not";
CM_ SG_ 306 WorkingSt_AVH "The signal indicates the woking status of AVH.
When AVH is standby , it means AVH is On, but not active braking.
When AVH is active , it means AVH is On and active braking.
When AVH is inactive, it  means AVH already on but not ready intervention";
CM_ SG_ 306 AvailableSt_AEB "This signal indicates the AEB function is available or not.";
CM_ SG_ 306 Intervention_AEB "The signal is indicates if the AEB function is intervention or not.";
CM_ SG_ 306 AvailableSt_ABP "This signal indicates the ABP function is available or not.";
CM_ SG_ 306 Intervention_ABP "The signal is indicates if the  ABP function is intervention or not.";
CM_ SG_ 306 AvailableSt_AWB "This signal indicates if the AWB function is available or not";
CM_ SG_ 306 Intervention_AWB "The signal is indicates if the AWB function is intervention or not.";
CM_ SG_ 306 AvailableSt_HBA "This signal indicates if the HBA is available or not";
CM_ SG_ 306 Intervention_HBA "This signal Indicates if the HBA is intervention or not.";
CM_ SG_ 306 Intervention_EmergencyBrake "The signal is indicates if the EmergencyBrake is Intervention or not.
This signal is used to light the flash when the speed is over 50kph and  brake deceleration over 0.6G or ABS is intervention";
CM_ SG_ 306 VehicleStandstillSt_ESC "The signal indicates the vehicle whether is in standstill or not.";
CM_ SG_ 306 BrakeLightCtrlCmd_ESC "The signal indicates the brake light control command.";
CM_ SG_ 306 Intervention_BTCS_F "The signal indicates if the BTCS of front axle is intervention or not.";
CM_ SG_ 306 Intervention_BTCS_R "The signal indicates if the BTCS of rear axle is intervention or not.";
CM_ SG_ 306 AvailableSt_MSR "This signal indicates if the MSR function is available or not";
CM_ SG_ 306 RoughRoadLevel "This signal Indicates the level of rough road. Inactive is defined as the vehicle is stop. Level 6 is defined as the most serious Rough level";
CM_ SG_ 306 BrakeHoldActive "This signal is used to EPB to judge that it is currently holding pressure. If holding pressure fails, EPB needs to actively clamp";
CM_ SG_ 306 ParkingRequestToEPB " indicates the release/lock brake request to EPB ";
CM_ SG_ 306 WorkingMode_ESC "This signal indicates the current working mode of ESC as the feedback to the  command of Drive Mode Selection ECU.";
CM_ SG_ 306 ModeChangeEnable_ESC "This signal indicates if the working mode of ESC can be changed or not.
";
CM_ SG_ 306 WorkingSt_CST "The signal indicates the woking status of CST.
When CST is Off, it means CST is disabled/init/default.
When CST is Standby , it means CST is On, but not active braking.
When CST is Intervention , it means CST is On and active braking.
When CST is Error, it  means CST is in error status.";
CM_ SG_ 306 LiveCounter_ESC_2_1 "The Livecounter is used to check the signal consistency of the messages . If the signals are consecutive, the LiveCounter should also be sequential in the way 0, 1, 2 ...X(depends on E2E usage), 0, 1 °≠";
CM_ SG_ 312 Checksum_ESC_5_1 "The checksum is used to check whether the data from the CPU buffer are shifted without transmission errors to the CAN communication controller buffer and vice versa.";
CM_ SG_ 312 ESC_TorqueReq_VMC_1 "This signal indicates the target torque request (wheel side vehcle level)";
CM_ SG_ 312 ESC_TorqueReqSt_VMC_1 "This signal indicates the status of signal ESC_TorqueReq_VMC.";
CM_ SG_ 312 ESC_TargetGearReq_VMC_1 "ESC request to change the lever position.";
CM_ SG_ 312 ESC_TargetGearReqEnable_VMC_1 "This signal is enable flag for gear request of ADAS Control";
CM_ SG_ 312 ESC_SuspendStatus_L2 "This signal indicates if the VMC system is suspend during L2 Function";
CM_ SG_ 312 ESC_EPBAvailableSt_L3 "This signal indicates EPB communication is available or not";
CM_ SG_ 312 ESC_CommunicationSt_L3 "This signal indicates L3 relevant network communication can be received or not.";
CM_ SG_ 312 ESC_UsedChannel_L3 "This signal indicates ESC feedback which communication channel is used for L3 control.";
CM_ SG_ 312 ESC_ControllerReleaseSt_L3 "This signal indicates ESC is available for L3 autodriving function or not.Release means IBC is available for L3 Control£¨Notrelease means IBC is not available for L3 Control.";
CM_ SG_ 312 ESC_SuspendStatusByDriver_L3 "This signal indicates if the VMC system is suspend during L3 Function(Driver)";
CM_ SG_ 312 ESC_SuspendStatusByOther_L3 "This signal indicates if the VMC system is suspend during L3 Function(Other)";
CM_ SG_ 312 ESC_VLC_Error_L12 "This signal indicates ESC is available for L12 autodriving function or not.";
CM_ SG_ 312 ESC_VLCSt "This signal indicates the vehicle longitudinal control status for L123 autodriving function.";
CM_ SG_ 312 ESC_VMC_Error_L3 "This signal indicates VMC system in ESC is available for L3 autodriving function or not.";
CM_ SG_ 312 ESC_AutoDriving_LC_Brakemode "This signal indicates Longitudinal controller brake mode
Only used in L3 function";
CM_ SG_ 312 ESC_AutoPark_LC_HPA_Avail "This signal indicates if theHPA function available or not ";
CM_ SG_ 312 ESC_AutoPark_LCSt "This signal indicates the longitudinal controller status";
CM_ SG_ 312 ESC_AutoPark_LC_APA_Avail "This signal indicates if the APA function available or not ";
CM_ SG_ 312 ESC_AutoPark_LC_RPA_Avail "This signal indicates if the RPA function available or not ";
CM_ SG_ 312 ESC_AutoPark_LC_AVP_Avail "This signal indicates if the AVP function available or not ";
CM_ SG_ 312 ESC_AutoPark_LCFailureSt "This signal indicates  the failure of the longitudinal controller";
CM_ SG_ 312 ESC_AutoPark_LC_BrakeMode "This signal indicates Longitudinal controller brake mode";
CM_ SG_ 312 ESC_HDCActiveForbidden "The signal indicates that ESC forbidden user active HDC on some condition such as auto pilot.";
CM_ SG_ 312 ESC_ESCOffForbidden "The signal indicates that ESC forbidden user turn off ESC on some condition such as auto pilot.";
CM_ SG_ 312 ESC_AVHActiveForbidden "The signal indicates that ESC forbidden user active AVH on some condition such as auto pilot.";
CM_ SG_ 312 ESC_ShutOffFinished "Indicates  that the shut off of VMC is finished.";
CM_ SG_ 312 ESC_BrakePadelOverride "This signal indicates driver brakes more than the system during AutoParking function. ";
CM_ SG_ 312 LiveCounter_ESC_5_1 "The Livecounter is used to check the signal consistency of the messages . If the signals are consecutive, the LiveCounter should also be sequential in the way 0, 1, 2 ...X(depends on E2E usage), 0, 1 °≠";
CM_ SG_ 193 Checksum_IBC_1 "The checksum is used to check whether the data from the CPU buffer are shifted without transmission errors to the CAN communication controller buffer and vice versa.";
CM_ SG_ 193 IBC_SimulatorPressure "The signal indicates the simulator Master cylinder pressure.";
CM_ SG_ 193 IBC_SimulatorPressureSt "The signal indicates the simulator pressure is valid or not.";
CM_ SG_ 193 IBC_SystemStatus "This signal indicates the status of IBC system.";
CM_ SG_ 193 IBC_PlungerPressure "The signal indicates the plunger pressure.";
CM_ SG_ 193 IBC_PlungerPressureSt "The signal indicates the plunger pressure is valid or not.";
CM_ SG_ 193 IBC_BrakePedalStatus_Q "This signal is the qualifier of brake pedal status.";
CM_ SG_ 193 IBC_InputRodStroke "The signal indicates the brake pedal stroke.";
CM_ SG_ 193 IBC_InputRodStrokeSt "The signal indicates  the brake pedal stroke is valid or not.";
CM_ SG_ 193 IBC_BrakeFluidWarning "This signal is the liquid level sensor signal on the oil pot.";
CM_ SG_ 193 IBC_BrakePedalStatus "This signal is the brake pedal status.";
CM_ SG_ 193 TwoFootBrakeSt "The signal indicates the driver pressed the brake pedal and the accelerator pedal at the same time";
CM_ SG_ 193 DegradedBBFWarning "This signal indicates degraded BBF(Brake Boost Function) warning";
CM_ SG_ 193 IBC_MILInfo "The MIL light is activated by IBC if the emission related errors are detected. This signal shall be reserved and fixed to 0x0 if there is no OBD requirement, e.g. EV vehicle.";
CM_ SG_ 193 FWAWarning "This signal indicates brake system over temperature warning.";
CM_ SG_ 193 IBC_RearWheelAngleRequest "Target RWS angle from VDC2.0
anticlockwise=positive, clockwise=negative";
CM_ SG_ 193 IBC_RearWheelAngleRequestSt "The signal indicates the Rear wheel angle request is valid or not.";
CM_ SG_ 193 IBC_VDCActive "The signal indicates the Vehicle instability is valid or not.";
CM_ SG_ 193 LiveCounter_IBC_1 "The Livecounter is used to check the signal consistency of the messages . If the signals are consecutive, the LiveCounter should also be sequential in the way 0, 1, 2 ...X(depends on E2E usage), 0, 1 °≠";
CM_ SG_ 1381 SECOC_FVReqCode_IBC "FV  request code. The signal shall be procceded following the byte order requirement in FAW-CYS-0033, i.e. SECOC spec";
CM_ SG_ 554 LimphomeSt_FL "The signal indicates the status of front left light LimphomeSt";
CM_ SG_ 554 PositionLightSt_FL "The signal indicates the status of front left position light.";
CM_ SG_ 554 DayRunningLightSt_FL "The signal indicates the status of front left day running light.";
CM_ SG_ 554 FogLightSt_FL "The signal is indicates the status of front left fog indicator.";
CM_ SG_ 554 TurningSt_FL "The signal indicates the driving status of the front left turn light.";
CM_ SG_ 554 TurningSt_LeftSide "The signal indicates the driving status of the left side turn light.";
CM_ SG_ 554 ADSLightSt_FL "The signal indicates the status of ADSLightSt_FL";
CM_ SG_ 554 CeremonyModeStatus_FL "This signal indicates the ceremony mode status of FL lamp.";
CM_ SG_ 554 TurnLightFaultSt_LeftSide "This signal shows left side turning light  fault status. ";
CM_ SG_ 554 HighBeamSt_FL "The signal  indicates the status of front left high beam indicator.";
CM_ SG_ 554 FoglightFaultSt_FL "This signal shows front left fog light fault status. ";
CM_ SG_ 554 HighbeamFaultSt_FL "This signal shows front left high beam light fault status. ";
CM_ SG_ 554 PositionLightFaultSt_FL "This signal shows front left position light fault status. ";
CM_ SG_ 554 DayRunningLightFaultSt_FL "This signal shows front left dayruning light fault status. ";
CM_ SG_ 554 TurningLightFaultSt_FL "This signal shows front left turning light  fault status. ";
CM_ SG_ 554 ADSLightFaultSt_FL "This signal shows ADSLightFaultSt_FL";
CM_ SG_ 554 CornerLampSt_FL "The signal is indicates the status of left corner light.";
CM_ SG_ 554 LampOTAMode_FL "This signal shows Lamp controller OTA mode. ";
CM_ SG_ 554 CornerLampFaultSt_FL "This signal shows left corner lamp fault status. ";
CM_ SG_ 554 ALS_Init_FL "This signal shows ALS_Init_FL init status. ";
CM_ SG_ 554 ALS_MotorFault_FL "This signal shows ALS_MotorFault_FL ";
CM_ SG_ 554 ALS_MotorPosition_FL "This signal shows ALS_MotorPosition_FL";
CM_ SG_ 502 Checksum_LampFL_2 "The checksum is used to check whether the data from the CPU buffer are shifted without transmission errors to the CAN communication controller buffer and vice versa.";
CM_ SG_ 502 LowBeamSt_FL "The signal  indicates the status of front left low beam indicator.";
CM_ SG_ 502 LowbeamFaultSt_FL "This signal shows front left low beam light fault status. ";
CM_ SG_ 502 LiveCounter_LampFL_2 "The Livecounter is used to check the signal consistency of the messages . If the signals are consecutive, the LiveCounter should also be sequential in the way 0, 1, 2 °≠15, 0, 1 °≠";
CM_ SG_ 810 LimphomeSt_FR "The signal indicates the status of front right light LimphomeSt";
CM_ SG_ 810 PositionLightSt_FR "The signal indicates the status of front right position light.";
CM_ SG_ 810 DayRunningLightSt_FR "The signal indicates the status of front right day running light.";
CM_ SG_ 810 FogLightSt_FR "The signal is indicates the status of front right fog indicator.";
CM_ SG_ 810 TurningSt_FR "The signal indicates the driving status of the front right turn light.";
CM_ SG_ 810 TurningSt_RightSide "The signal indicates the driving status of the right side turn light.";
CM_ SG_ 810 ADSLightSt_FR "The signal indicates the status of ADSLightSt_FR";
CM_ SG_ 810 CeremonyModeStatus_FR "This signal indicates the ceremony mode status of FR lamp.";
CM_ SG_ 810 TurnLightFaultSt_RightSide "This signal shows right side turning light  fault status. ";
CM_ SG_ 810 HighBeamSt_FR "The signal  indicates the status of front right high beam indicator.";
CM_ SG_ 810 FoglightFaultSt_FR "This signal shows front right fog light fault status. ";
CM_ SG_ 810 HighbeamFaultSt_FR "This signal shows front right high beam light fault status. ";
CM_ SG_ 810 PositionLightFaultSt_FR "This signal shows front right position light fault status. ";
CM_ SG_ 810 DayRunningLightFaultSt_FR "This signal shows front right dayruning light fault status. ";
CM_ SG_ 810 TurningLightFaultSt_FR "This signal shows front right turning light  fault status. ";
CM_ SG_ 810 ADSLightFaultSt_FR "This signal shows ADSLightFaultSt_FR";
CM_ SG_ 810 CornerLampSt_FR "The signal is indicates the status of right corner light.";
CM_ SG_ 810 LampOTAMode_FR "This signal shows Lamp controller OTA mode. ";
CM_ SG_ 810 CornerLampFaultSt_FR "This signal shows right corner lamp fault status. ";
CM_ SG_ 810 ALS_Init_FR "This signal shows ALS_Init_FR init status. ";
CM_ SG_ 810 ALS_MotorFault_FR "This signal shows ALS_MotorFault_FR";
CM_ SG_ 810 ALS_MotorPosition_FR "This signal shows ALS_MotorPosition_FR";
CM_ SG_ 501 Checksum_LampFR_2 "The checksum is used to check whether the data from the CPU buffer are shifted without transmission errors to the CAN communication controller buffer and vice versa.";
CM_ SG_ 501 LowBeamSt_FR "The signal  indicates the status of front right low beam indicator.";
CM_ SG_ 501 LowbeamFaultSt_FR "This signal shows front right  low beam light fault status. ";
CM_ SG_ 501 LiveCounter_LampFR_2 "The Livecounter is used to check the signal consistency of the messages . If the signals are consecutive, the LiveCounter should also be sequential in the way 0, 1, 2 °≠15, 0, 1 °≠";
CM_ SG_ 1210 SoftwareNumber_EPS "TThis signal indicates the software number. The signal shll be proceeded following the requirement of OTS spec.";
CM_ SG_ 1210 HardwareRelated_ConfigID_EPS "This signal indicates the hardware related information about config ID.The signal shll be proceeded following the requirement of OTS spec.";
CM_ SG_ 1260 SoftwareNumber_IBC "TThis signal indicates the software number. The signal shll be proceeded following the requirement of OTS spec.";
CM_ SG_ 1260 HardwareRelated_ConfigID_IBC "This signal indicates the hardware related information about config ID.The signal shll be proceeded following the requirement of OTS spec.";
CM_ SG_ 1272 SoftwareNumber_MCUF "TThis signal indicates the software number. The signal shll be proceeded following the requirement of OTS spec.";
CM_ SG_ 1272 HardwareRelated_ConfigID_MCUF "This signal indicates the hardware related information about config ID.The signal shll be proceeded following the requirement of OTS spec.";
CM_ SG_ 1193 SoftwareNumber_PDCF "TThis signal indicates the software number. The signal shll be proceeded following the requirement of OTS spec.";
CM_ SG_ 1193 HardwareRelated_ConfigID_PDCF "This signal indicates the hardware related information about config ID.The signal shll be proceeded following the requirement of OTS spec.";
CM_ SG_ 1065 SoftwareNumber_PDCM "TThis signal indicates the software number. The signal shall be proceeded following the requirement of OTS spec.";
CM_ SG_ 1065 HardwareRelated_ConfigID_PDCM "This signal indicates the hardware related information about config ID.The signal shall be proceeded following the requirement of OTS spec.";
CM_ SG_ 1199 SoftwareNumber_RBU "TThis signal indicates the software number. The signal shll be proceeded following the requirement of OTS spec.";
CM_ SG_ 1199 HardwareRelated_ConfigID_RBU "This signal indicates the hardware related information about config ID.The signal shll be proceeded following the requirement of OTS spec.";
CM_ SG_ 1214 SoftwareNumber_RWS "TThis signal indicates the software number. The signal shll be proceeded following the requirement of OTS spec.";
CM_ SG_ 1214 HardwareRelated_ConfigID_RWS "This signal indicates the hardware related information about config ID.The signal shll be proceeded following the requirement of OTS spec.";
CM_ SG_ 1037 SoftwareNumber_LAMP_FL "TThis signal indicates the software number. The signal shall be proceeded following the requirement of OTS spec.";
CM_ SG_ 1037 HardwareRelated_ConfigID_LAMP_FL "This signal indicates the hardware related information about config ID.The signal shall be proceeded following the requirement of OTS spec.";
CM_ SG_ 1211 SoftwareNumber_LAMP_FR "TThis signal indicates the software number. The signal shll be proceeded following the requirement of OTS spec.";
CM_ SG_ 1211 HardwareRelated_ConfigID_LAMP_FR "This signal indicates the hardware related information about config ID.The signal shll be proceeded following the requirement of OTS spec.";
CM_ SG_ 1215 SoftwareNumber_PNG1 "TThis signal indicates the software number. The signal shll be proceeded following the requirement of OTS spec.";
CM_ SG_ 1215 HardwareRelated_ConfigID_PNG1 "This signal indicates the hardware related information about config ID.The signal shll be proceeded following the requirement of OTS spec.";
CM_ SG_ 1276 SoftwareNumber_PNG2 "TThis signal indicates the software number. The signal shll be proceeded following the requirement of OTS spec.";
CM_ SG_ 1276 HardwareRelated_ConfigID_PNG2 "This signal indicates the hardware related information about config ID.The signal shll be proceeded following the requirement of OTS spec.";
CM_ SG_ 1377 SECOC_FVReqCode_PDCF "FV  request code. The signal shall be procceded following the byte order requirement in FAW-CYS-0033, i.e. SECOC spec";
BA_DEF_ BO_  "VFrameFormat" ENUM  "StandardCAN","ExtendedCAN","reserved","reserved","reserved","reserved","reserved","reserved","reserved","reserved","reserved","reserved","reserved","reserved","StandardCAN_FD","ExtendedCAN_FD";
BA_DEF_  "ProtocolType" STRING ;
BA_DEF_ BU_  "NmAsrCanMsgReducedTime" INT 0 65535;
BA_DEF_ BO_  "GenMsgILSupport" ENUM  "No","Yes";
BA_DEF_ BO_  "CanTpSTmin" INT 0 0;
BA_DEF_ BO_  "CanTpFcFrameId" HEX 0 2147483647;
BA_DEF_  "NmAsrBaseAddress" HEX 0 2047;
BA_DEF_  "NmAsrMessageCount" INT 1 256;
BA_DEF_  "NmType" STRING ;
BA_DEF_  "Baudrate" INT 0 5000000;
BA_DEF_  "Manufacturer" STRING ;
BA_DEF_  "NmAsrWaitBusSleepTime" INT 0 65535;
BA_DEF_  "NmAsrTimeoutTime" INT 0 65535;
BA_DEF_  "NmAsrRepeatMessageTime" INT 0 65535;
BA_DEF_  "NmAsrCanMsgCycleTime" INT 0 65535;
BA_DEF_  "BusType" STRING ;
BA_DEF_  "DBName" STRING ;
BA_DEF_  "VersionNumber" INT 0 0;
BA_DEF_  "VersionDay" INT 0 31;
BA_DEF_  "VersionMonth" INT 0 12;
BA_DEF_  "VersionYear" INT 0 99;
BA_DEF_ BO_  "GenMsgSendType" ENUM  "Cyclic","not_used","not_used","not_used","not_used","Cyclic","not_used","IfActive","NoMsgSendType","Spontaneous","CyclicAndSpontaneous","NoMsgSendType";
BA_DEF_ BO_  "GenMsgCycleTime" INT 0 0;
BA_DEF_ SG_  "GenSigSendType" ENUM  "Cyclic","OnWrite","OnWriteWithRepetition","OnChange","OnChangeWithRepetition","IfActive","IfActiveWithRepetition","NoSigSendType";
BA_DEF_ SG_  "GenSigStartValue" INT 0 0;
BA_DEF_ SG_  "GenSigInvalidValue" INT 0 0;
BA_DEF_ SG_  "GenSigStartRemark" STRING ;
BA_DEF_ SG_  "GenSigInvalidRemark" STRING ;
BA_DEF_ SG_  "SystemSignalLongSymbol" STRING ;
BA_DEF_REL_ BU_SG_REL_  "GenSigTimeoutTime" INT 0 5000;
BA_DEF_DEF_  "VFrameFormat" "ExtendedCAN_FD";
BA_DEF_DEF_  "ProtocolType" "*";
BA_DEF_DEF_  "NmAsrCanMsgReducedTime" 50;
BA_DEF_DEF_  "GenMsgILSupport" "Yes";
BA_DEF_DEF_  "CanTpSTmin" 1;
BA_DEF_DEF_  "CanTpFcFrameId" 2147483647;
BA_DEF_DEF_  "NmAsrBaseAddress" 1280;
BA_DEF_DEF_  "NmAsrMessageCount" 128;
BA_DEF_DEF_  "NmType" "NmAsr";
BA_DEF_DEF_  "Baudrate" 2000000;
BA_DEF_DEF_  "Manufacturer" "FAW";
BA_DEF_DEF_  "NmAsrWaitBusSleepTime" 750;
BA_DEF_DEF_  "NmAsrTimeoutTime" 1000;
BA_DEF_DEF_  "NmAsrRepeatMessageTime" 400;
BA_DEF_DEF_  "NmAsrCanMsgCycleTime" 100;
BA_DEF_DEF_  "BusType" "CAN";
BA_DEF_DEF_  "DBName" "";
BA_DEF_DEF_  "VersionNumber" 0;
BA_DEF_DEF_  "VersionDay" 1;
BA_DEF_DEF_  "VersionMonth" 1;
BA_DEF_DEF_  "VersionYear" 0;
BA_DEF_DEF_  "GenMsgSendType" "Cyclic";
BA_DEF_DEF_  "GenMsgCycleTime" 0;
BA_DEF_DEF_  "GenSigSendType" "NoSigSendType";
BA_DEF_DEF_  "GenSigStartValue" 0;
BA_DEF_DEF_  "GenSigInvalidValue" 0;
BA_DEF_DEF_  "GenSigStartRemark" "";
BA_DEF_DEF_  "GenSigInvalidRemark" "";
BA_DEF_DEF_REL_ "GenSigTimeoutTime" 0;
BA_DEF_DEF_  "SystemSignalLongSymbol" "";
BA_ "VersionNumber" 0.8;
BA_ "VersionDay" 27;
BA_ "VersionMonth" 12;
BA_ "VersionYear" 22;
BA_ "BusType" "CAN FD";
BA_ "DBName" "FAW_E001B_Backbone_PDCF_CANDBC";
BA_ "GenMsgCycleTime" BO_ 192 10;
BA_ "VFrameFormat" BO_ 192 14;
BA_ "GenMsgCycleTime" BO_ 206 10;
BA_ "VFrameFormat" BO_ 206 14;
BA_ "GenMsgCycleTime" BO_ 208 10;
BA_ "VFrameFormat" BO_ 208 14;
BA_ "GenMsgCycleTime" BO_ 336 20;
BA_ "VFrameFormat" BO_ 336 14;
BA_ "GenMsgCycleTime" BO_ 337 20;
BA_ "VFrameFormat" BO_ 337 14;
BA_ "GenMsgCycleTime" BO_ 195 10;
BA_ "VFrameFormat" BO_ 195 14;
BA_ "GenMsgCycleTime" BO_ 306 10;
BA_ "VFrameFormat" BO_ 306 14;
BA_ "GenMsgCycleTime" BO_ 312 20;
BA_ "VFrameFormat" BO_ 312 14;
BA_ "GenMsgCycleTime" BO_ 193 10;
BA_ "VFrameFormat" BO_ 193 14;
BA_ "GenMsgCycleTime" BO_ 1381 50;
BA_ "VFrameFormat" BO_ 1381 14;
BA_ "GenMsgCycleTime" BO_ 554 100;
BA_ "VFrameFormat" BO_ 554 14;
BA_ "GenMsgCycleTime" BO_ 502 100;
BA_ "VFrameFormat" BO_ 502 14;
BA_ "GenMsgCycleTime" BO_ 810 100;
BA_ "VFrameFormat" BO_ 810 14;
BA_ "GenMsgCycleTime" BO_ 501 100;
BA_ "VFrameFormat" BO_ 501 14;
BA_ "GenMsgCycleTime" BO_ 1210 5000;
BA_ "VFrameFormat" BO_ 1210 14;
BA_ "GenMsgCycleTime" BO_ 1260 5000;
BA_ "VFrameFormat" BO_ 1260 14;
BA_ "GenMsgCycleTime" BO_ 1272 5000;
BA_ "VFrameFormat" BO_ 1272 14;
BA_ "GenMsgCycleTime" BO_ 1193 5000;
BA_ "VFrameFormat" BO_ 1193 14;
BA_ "GenMsgCycleTime" BO_ 1065 5000;
BA_ "VFrameFormat" BO_ 1065 14;
BA_ "GenMsgCycleTime" BO_ 1199 5000;
BA_ "VFrameFormat" BO_ 1199 14;
BA_ "GenMsgCycleTime" BO_ 1214 5000;
BA_ "VFrameFormat" BO_ 1214 14;
BA_ "GenMsgCycleTime" BO_ 1037 5000;
BA_ "VFrameFormat" BO_ 1037 14;
BA_ "GenMsgCycleTime" BO_ 1211 5000;
BA_ "VFrameFormat" BO_ 1211 14;
BA_ "GenMsgCycleTime" BO_ 1215 5000;
BA_ "VFrameFormat" BO_ 1215 14;
BA_ "GenMsgCycleTime" BO_ 1276 5000;
BA_ "VFrameFormat" BO_ 1276 14;
BA_ "GenMsgCycleTime" BO_ 1377 50;
BA_ "VFrameFormat" BO_ 1377 14;
BA_ "GenSigStartRemark" SG_ 192 Checksum_ABS_1 "V";
BA_ "GenSigStartValue" SG_ 192 WheelSpeed_FL 32766;
BA_ "GenSigInvalidValue" SG_ 192 WheelSpeed_FL 32767;
BA_ "GenSigStartRemark" SG_ 192 WheelSpeed_FL "O";
BA_ "GenSigInvalidRemark" SG_ 192 WheelSpeed_FL "O";
BA_ "GenSigStartValue" SG_ 192 WheelSpeed_FR 32766;
BA_ "GenSigInvalidValue" SG_ 192 WheelSpeed_FR 32767;
BA_ "GenSigStartRemark" SG_ 192 WheelSpeed_FR "O";
BA_ "GenSigInvalidRemark" SG_ 192 WheelSpeed_FR "O";
BA_ "GenSigStartValue" SG_ 192 WheelSpeed_RL 32766;
BA_ "GenSigInvalidValue" SG_ 192 WheelSpeed_RL 32767;
BA_ "GenSigStartRemark" SG_ 192 WheelSpeed_RL "O";
BA_ "GenSigInvalidRemark" SG_ 192 WheelSpeed_RL "O";
BA_ "GenSigStartValue" SG_ 192 WheelSpeed_RR 32766;
BA_ "GenSigInvalidValue" SG_ 192 WheelSpeed_RR 32767;
BA_ "GenSigStartRemark" SG_ 192 WheelSpeed_RR "O";
BA_ "GenSigInvalidRemark" SG_ 192 WheelSpeed_RR "O";
BA_ "GenSigStartValue" SG_ 192 WheelPulse_FL 254;
BA_ "GenSigInvalidValue" SG_ 192 WheelPulse_FL 255;
BA_ "GenSigStartRemark" SG_ 192 WheelPulse_FL "O";
BA_ "GenSigInvalidRemark" SG_ 192 WheelPulse_FL "O";
BA_ "GenSigStartValue" SG_ 192 WheelPulse_FR 254;
BA_ "GenSigInvalidValue" SG_ 192 WheelPulse_FR 255;
BA_ "GenSigStartRemark" SG_ 192 WheelPulse_FR "O";
BA_ "GenSigInvalidRemark" SG_ 192 WheelPulse_FR "O";
BA_ "GenSigStartValue" SG_ 192 WheelPulse_RL 254;
BA_ "GenSigInvalidValue" SG_ 192 WheelPulse_RL 255;
BA_ "GenSigStartRemark" SG_ 192 WheelPulse_RL "O";
BA_ "GenSigInvalidRemark" SG_ 192 WheelPulse_RL "O";
BA_ "GenSigStartValue" SG_ 192 WheelPulse_RR 254;
BA_ "GenSigInvalidValue" SG_ 192 WheelPulse_RR 255;
BA_ "GenSigStartRemark" SG_ 192 WheelPulse_RR "O";
BA_ "GenSigInvalidRemark" SG_ 192 WheelPulse_RR "O";
BA_ "GenSigStartValue" SG_ 192 VehicleSpeed 32766;
BA_ "GenSigInvalidValue" SG_ 192 VehicleSpeed 32767;
BA_ "GenSigStartRemark" SG_ 192 VehicleSpeed "O";
BA_ "GenSigInvalidRemark" SG_ 192 VehicleSpeed "O";
BA_ "GenSigInvalidValue" SG_ 192 BrakeTorqueOnWheels 4095;
BA_ "GenSigInvalidRemark" SG_ 192 BrakeTorqueOnWheels "O";
BA_ "GenSigStartValue" SG_ 192 EstimatedWheelPressure_FL 16382;
BA_ "GenSigInvalidValue" SG_ 192 EstimatedWheelPressure_FL 16383;
BA_ "GenSigStartValue" SG_ 192 EstimatedWheelPressure_FR 16382;
BA_ "GenSigInvalidValue" SG_ 192 EstimatedWheelPressure_FR 16383;
BA_ "GenSigStartValue" SG_ 192 EstimatedWheelPressure_RL 16382;
BA_ "GenSigInvalidValue" SG_ 192 EstimatedWheelPressure_RL 16383;
BA_ "GenSigStartValue" SG_ 192 EstimatedWheelPressure_RR 16382;
BA_ "GenSigInvalidValue" SG_ 192 EstimatedWheelPressure_RR 16383;
BA_ "GenSigStartRemark" SG_ 206 Checksum_EPBMaster_1 "V";
BA_ "SystemSignalLongSymbol" SG_ 206 BrakeForceNotEnoughWarning_EPBMa "BrakeForceNotEnoughWarning_EPBMaster";
BA_ "GenSigStartValue" SG_ 206 EPBMasterDecelerationRequest 4094;
BA_ "GenSigInvalidValue" SG_ 206 EPBMasterDecelerationRequest 4095;
BA_ "GenSigStartRemark" SG_ 206 EPBMasterDecelerationRequest "O";
BA_ "GenSigInvalidRemark" SG_ 206 EPBMasterDecelerationRequest "O";
BA_ "SystemSignalLongSymbol" SG_ 206 StatusEPBMasterDecelerationReque "StatusEPBMasterDecelerationRequest";
BA_ "GenSigStartRemark" SG_ 206 AutoLockFunctionSt_EPBMaster_1 "L";
BA_ "GenSigStartRemark" SG_ 208 Checksum_EPS1_SAS_1 "V";
BA_ "GenSigInvalidValue" SG_ 208 EPS1_SteeringWheelAngle 32767;
BA_ "GenSigInvalidRemark" SG_ 208 EPS1_SteeringWheelAngle "O";
BA_ "GenSigInvalidValue" SG_ 208 EPS1_SteeringWheelSpeed 32767;
BA_ "GenSigInvalidRemark" SG_ 208 EPS1_SteeringWheelSpeed "O";
BA_ "GenSigStartValue" SG_ 208 EPS1_SAS_St 1;
BA_ "GenSigStartRemark" SG_ 336 Checksum_EPS_1_1 "V";
BA_ "GenSigStartValue" SG_ 336 EPS_1_HandSteeringTorque 1022;
BA_ "GenSigInvalidValue" SG_ 336 EPS_1_HandSteeringTorque 1023;
BA_ "GenSigStartValue" SG_ 336 EPS_1_OverlayInputTorque 1022;
BA_ "GenSigInvalidValue" SG_ 336 EPS_1_OverlayInputTorque 1023;
BA_ "GenSigInvalidValue" SG_ 336 EPS_1_WorkingMode_DMS 15;
BA_ "GenSigStartRemark" SG_ 337 Checksum_EPS_1_2 "V";
BA_ "GenSigStartValue" SG_ 337 EPS_1_PullingTorque 1022;
BA_ "GenSigInvalidValue" SG_ 337 EPS_1_PullingTorque 1023;
BA_ "GenSigStartRemark" SG_ 195 Checksum_ESC_1_W "V";
BA_ "GenSigStartValue" SG_ 195 TorqueReductionFast_TCS_FrontWhe 8190;
BA_ "GenSigInvalidValue" SG_ 195 TorqueReductionFast_TCS_FrontWhe 8191;
BA_ "SystemSignalLongSymbol" SG_ 195 TorqueReductionFast_TCS_FrontWhe "TorqueReductionFast_TCS_FrontWheel";
BA_ "GenSigStartValue" SG_ 195 TorqueIncrease_MSR_FrontWheel 16382;
BA_ "GenSigInvalidValue" SG_ 195 TorqueIncrease_MSR_FrontWheel 16383;
BA_ "GenSigStartValue" SG_ 195 TorqueReductionFast_TCS_RearWhee 8190;
BA_ "GenSigInvalidValue" SG_ 195 TorqueReductionFast_TCS_RearWhee 8191;
BA_ "SystemSignalLongSymbol" SG_ 195 TorqueReductionFast_TCS_RearWhee "TorqueReductionFast_TCS_RearWheel";
BA_ "GenSigStartValue" SG_ 195 TorqueIncrease_MSR_RearWheel 16382;
BA_ "GenSigInvalidValue" SG_ 195 TorqueIncrease_MSR_RearWheel 16383;
BA_ "GenSigStartValue" SG_ 195 ESC_RegenerationTorqueRequest 8190;
BA_ "GenSigInvalidValue" SG_ 195 ESC_RegenerationTorqueRequest 8191;
BA_ "SystemSignalLongSymbol" SG_ 195 TorqReductionFastSt_TCS_FrontWhe "TorqReductionFastSt_TCS_FrontWheel";
BA_ "SystemSignalLongSymbol" SG_ 195 TorqReductionFastSt_TCS_RearWhee "TorqReductionFastSt_TCS_RearWheel";
BA_ "SystemSignalLongSymbol" SG_ 195 ESC_StatusRegenerationTorqueRequ "ESC_StatusRegenerationTorqueRequest";
BA_ "GenSigStartValue" SG_ 195 ESC_FrontBiasMax 126;
BA_ "GenSigInvalidValue" SG_ 195 ESC_FrontBiasMax 127;
BA_ "GenSigStartValue" SG_ 195 ESC_RearBiasMax 126;
BA_ "GenSigInvalidValue" SG_ 195 ESC_RearBiasMax 127;
BA_ "GenSigStartRemark" SG_ 306 Checksum_ESC_2_1 "V";
BA_ "GenSigStartValue" SG_ 306 WorkingSt_ESC 1;
BA_ "GenSigStartValue" SG_ 306 AvailableSt_HBA 1;
BA_ "GenSigInvalidValue" SG_ 306 RoughRoadLevel 7;
BA_ "GenSigInvalidValue" SG_ 306 WorkingMode_ESC 15;
BA_ "GenSigStartRemark" SG_ 312 Checksum_ESC_5_1 "V";
BA_ "GenSigStartValue" SG_ 312 ESC_TorqueReq_VMC_1 131070;
BA_ "GenSigInvalidValue" SG_ 312 ESC_TorqueReq_VMC_1 131071;
BA_ "GenSigInvalidValue" SG_ 312 ESC_VMC_Error_L3 7;
BA_ "GenSigInvalidValue" SG_ 312 ESC_AutoPark_LCSt 7;
BA_ "GenSigInvalidValue" SG_ 312 ESC_AutoPark_LCFailureSt 15;
BA_ "GenSigStartRemark" SG_ 193 Checksum_IBC_1 "V";
BA_ "GenSigStartValue" SG_ 193 IBC_SimulatorPressure 1022;
BA_ "GenSigInvalidValue" SG_ 193 IBC_SimulatorPressure 1023;
BA_ "GenSigStartRemark" SG_ 193 IBC_SimulatorPressure "O";
BA_ "GenSigInvalidRemark" SG_ 193 IBC_SimulatorPressure "O";
BA_ "GenSigStartValue" SG_ 193 IBC_PlungerPressure 1022;
BA_ "GenSigInvalidValue" SG_ 193 IBC_PlungerPressure 1023;
BA_ "GenSigStartRemark" SG_ 193 IBC_PlungerPressure "O";
BA_ "GenSigInvalidRemark" SG_ 193 IBC_PlungerPressure "O";
BA_ "GenSigStartValue" SG_ 193 IBC_InputRodStroke 1022;
BA_ "GenSigInvalidValue" SG_ 193 IBC_InputRodStroke 1023;
BA_ "GenSigStartRemark" SG_ 193 IBC_InputRodStroke "O";
BA_ "GenSigInvalidRemark" SG_ 193 IBC_InputRodStroke "O";
BA_ "GenSigInvalidValue" SG_ 193 IBC_BrakeFluidWarning 3;
BA_ "GenSigInvalidValue" SG_ 193 IBC_BrakePedalStatus 3;
BA_ "GenSigStartValue" SG_ 193 IBC_RearWheelAngleRequest 4094;
BA_ "GenSigInvalidValue" SG_ 193 IBC_RearWheelAngleRequest 4095;
BA_ "GenSigStartRemark" SG_ 502 Checksum_LampFL_2 "V";
BA_ "GenSigStartRemark" SG_ 501 Checksum_LampFR_2 "V";
BA_REL_ "GenSigTimeoutTime" BU_SG_REL_ VDC821 SG_ 192 Checksum_ABS_1 100;
BA_REL_ "GenSigTimeoutTime" BU_SG_REL_ VDC397 SG_ 192 Checksum_ABS_1 100;
BA_REL_ "GenSigTimeoutTime" BU_SG_REL_ HAD3971 SG_ 192 Checksum_ABS_1 100;
BA_REL_ "GenSigTimeoutTime" BU_SG_REL_ PDCM SG_ 192 Checksum_ABS_1 100;
BA_REL_ "GenSigTimeoutTime" BU_SG_REL_ PDCR SG_ 192 Checksum_ABS_1 100;
BA_REL_ "GenSigTimeoutTime" BU_SG_REL_ VDC821 SG_ 192 WheelSpeed_FL 100;
BA_REL_ "GenSigTimeoutTime" BU_SG_REL_ VDC397 SG_ 192 WheelSpeed_FL 100;
BA_REL_ "GenSigTimeoutTime" BU_SG_REL_ HAD3971 SG_ 192 WheelSpeed_FL 100;
BA_REL_ "GenSigTimeoutTime" BU_SG_REL_ PDCR SG_ 192 WheelSpeed_FL 100;
BA_REL_ "GenSigTimeoutTime" BU_SG_REL_ VDC821 SG_ 192 WheelSpeed_FR 100;
BA_REL_ "GenSigTimeoutTime" BU_SG_REL_ VDC397 SG_ 192 WheelSpeed_FR 100;
BA_REL_ "GenSigTimeoutTime" BU_SG_REL_ HAD3971 SG_ 192 WheelSpeed_FR 100;
BA_REL_ "GenSigTimeoutTime" BU_SG_REL_ PDCR SG_ 192 WheelSpeed_FR 100;
BA_REL_ "GenSigTimeoutTime" BU_SG_REL_ VDC821 SG_ 192 WheelSpeed_RL 100;
BA_REL_ "GenSigTimeoutTime" BU_SG_REL_ VDC397 SG_ 192 WheelSpeed_RL 100;
BA_REL_ "GenSigTimeoutTime" BU_SG_REL_ HAD3971 SG_ 192 WheelSpeed_RL 100;
BA_REL_ "GenSigTimeoutTime" BU_SG_REL_ PDCR SG_ 192 WheelSpeed_RL 100;
BA_REL_ "GenSigTimeoutTime" BU_SG_REL_ VDC821 SG_ 192 WheelSpeed_RR 100;
BA_REL_ "GenSigTimeoutTime" BU_SG_REL_ VDC397 SG_ 192 WheelSpeed_RR 100;
BA_REL_ "GenSigTimeoutTime" BU_SG_REL_ HAD3971 SG_ 192 WheelSpeed_RR 100;
BA_REL_ "GenSigTimeoutTime" BU_SG_REL_ PDCR SG_ 192 WheelSpeed_RR 100;
BA_REL_ "GenSigTimeoutTime" BU_SG_REL_ VDC821 SG_ 192 WheelPulse_FL 100;
BA_REL_ "GenSigTimeoutTime" BU_SG_REL_ VDC397 SG_ 192 WheelPulse_FL 100;
BA_REL_ "GenSigTimeoutTime" BU_SG_REL_ HAD3971 SG_ 192 WheelPulse_FL 100;
BA_REL_ "GenSigTimeoutTime" BU_SG_REL_ PDCR SG_ 192 WheelPulse_FL 100;
BA_REL_ "GenSigTimeoutTime" BU_SG_REL_ VDC821 SG_ 192 WheelPulse_FR 100;
BA_REL_ "GenSigTimeoutTime" BU_SG_REL_ VDC397 SG_ 192 WheelPulse_FR 100;
BA_REL_ "GenSigTimeoutTime" BU_SG_REL_ HAD3971 SG_ 192 WheelPulse_FR 100;
BA_REL_ "GenSigTimeoutTime" BU_SG_REL_ PDCR SG_ 192 WheelPulse_FR 100;
BA_REL_ "GenSigTimeoutTime" BU_SG_REL_ VDC821 SG_ 192 WheelPulse_RL 100;
BA_REL_ "GenSigTimeoutTime" BU_SG_REL_ VDC397 SG_ 192 WheelPulse_RL 100;
BA_REL_ "GenSigTimeoutTime" BU_SG_REL_ HAD3971 SG_ 192 WheelPulse_RL 100;
BA_REL_ "GenSigTimeoutTime" BU_SG_REL_ PDCR SG_ 192 WheelPulse_RL 100;
BA_REL_ "GenSigTimeoutTime" BU_SG_REL_ VDC821 SG_ 192 WheelPulse_RR 100;
BA_REL_ "GenSigTimeoutTime" BU_SG_REL_ VDC397 SG_ 192 WheelPulse_RR 100;
BA_REL_ "GenSigTimeoutTime" BU_SG_REL_ HAD3971 SG_ 192 WheelPulse_RR 100;
BA_REL_ "GenSigTimeoutTime" BU_SG_REL_ PDCR SG_ 192 WheelPulse_RR 100;
BA_REL_ "GenSigTimeoutTime" BU_SG_REL_ VDC821 SG_ 192 WheelSpeedDirection_FL 100;
BA_REL_ "GenSigTimeoutTime" BU_SG_REL_ VDC397 SG_ 192 WheelSpeedDirection_FL 100;
BA_REL_ "GenSigTimeoutTime" BU_SG_REL_ PDCR SG_ 192 WheelSpeedDirection_FL 100;
BA_REL_ "GenSigTimeoutTime" BU_SG_REL_ VDC821 SG_ 192 WheelSpeedDirection_FR 100;
BA_REL_ "GenSigTimeoutTime" BU_SG_REL_ VDC397 SG_ 192 WheelSpeedDirection_FR 100;
BA_REL_ "GenSigTimeoutTime" BU_SG_REL_ PDCR SG_ 192 WheelSpeedDirection_FR 100;
BA_REL_ "GenSigTimeoutTime" BU_SG_REL_ VDC821 SG_ 192 WheelSpeedDirection_RL 100;
BA_REL_ "GenSigTimeoutTime" BU_SG_REL_ VDC397 SG_ 192 WheelSpeedDirection_RL 100;
BA_REL_ "GenSigTimeoutTime" BU_SG_REL_ PDCR SG_ 192 WheelSpeedDirection_RL 100;
BA_REL_ "GenSigTimeoutTime" BU_SG_REL_ VDC821 SG_ 192 WheelSpeedDirection_RR 100;
BA_REL_ "GenSigTimeoutTime" BU_SG_REL_ VDC397 SG_ 192 WheelSpeedDirection_RR 100;
BA_REL_ "GenSigTimeoutTime" BU_SG_REL_ PDCR SG_ 192 WheelSpeedDirection_RR 100;
BA_REL_ "GenSigTimeoutTime" BU_SG_REL_ VDC821 SG_ 192 WheelSpeedDirection_FL_Q 100;
BA_REL_ "GenSigTimeoutTime" BU_SG_REL_ VDC397 SG_ 192 WheelSpeedDirection_FL_Q 100;
BA_REL_ "GenSigTimeoutTime" BU_SG_REL_ PDCR SG_ 192 WheelSpeedDirection_FL_Q 100;
BA_REL_ "GenSigTimeoutTime" BU_SG_REL_ VDC821 SG_ 192 WheelSpeedDirection_FR_Q 100;
BA_REL_ "GenSigTimeoutTime" BU_SG_REL_ VDC397 SG_ 192 WheelSpeedDirection_FR_Q 100;
BA_REL_ "GenSigTimeoutTime" BU_SG_REL_ PDCR SG_ 192 WheelSpeedDirection_FR_Q 100;
BA_REL_ "GenSigTimeoutTime" BU_SG_REL_ VDC821 SG_ 192 WheelSpeedDirection_RL_Q 100;
BA_REL_ "GenSigTimeoutTime" BU_SG_REL_ VDC397 SG_ 192 WheelSpeedDirection_RL_Q 100;
BA_REL_ "GenSigTimeoutTime" BU_SG_REL_ PDCR SG_ 192 WheelSpeedDirection_RL_Q 100;
BA_REL_ "GenSigTimeoutTime" BU_SG_REL_ VDC821 SG_ 192 WheelSpeedDirection_RR_Q 100;
BA_REL_ "GenSigTimeoutTime" BU_SG_REL_ VDC397 SG_ 192 WheelSpeedDirection_RR_Q 100;
BA_REL_ "GenSigTimeoutTime" BU_SG_REL_ PDCR SG_ 192 WheelSpeedDirection_RR_Q 100;
BA_REL_ "GenSigTimeoutTime" BU_SG_REL_ VDC821 SG_ 192 VehicleSpeed 100;
BA_REL_ "GenSigTimeoutTime" BU_SG_REL_ VDC397 SG_ 192 VehicleSpeed 100;
BA_REL_ "GenSigTimeoutTime" BU_SG_REL_ HAD3971 SG_ 192 VehicleSpeed 100;
BA_REL_ "GenSigTimeoutTime" BU_SG_REL_ PDCM SG_ 192 VehicleSpeed 100;
BA_REL_ "GenSigTimeoutTime" BU_SG_REL_ PDCR SG_ 192 VehicleSpeed 100;
BA_REL_ "GenSigTimeoutTime" BU_SG_REL_ VDC821 SG_ 192 VehiclSpeed_Q 100;
BA_REL_ "GenSigTimeoutTime" BU_SG_REL_ VDC397 SG_ 192 VehiclSpeed_Q 100;
BA_REL_ "GenSigTimeoutTime" BU_SG_REL_ HAD3971 SG_ 192 VehiclSpeed_Q 100;
BA_REL_ "GenSigTimeoutTime" BU_SG_REL_ PDCR SG_ 192 VehiclSpeed_Q 100;
BA_REL_ "GenSigTimeoutTime" BU_SG_REL_ VDC821 SG_ 192 DrivingDirection 100;
BA_REL_ "GenSigTimeoutTime" BU_SG_REL_ VDC397 SG_ 192 DrivingDirection 100;
BA_REL_ "GenSigTimeoutTime" BU_SG_REL_ HAD3971 SG_ 192 DrivingDirection 100;
BA_REL_ "GenSigTimeoutTime" BU_SG_REL_ VDC821 SG_ 192 DrivingDirection_Q 100;
BA_REL_ "GenSigTimeoutTime" BU_SG_REL_ VDC397 SG_ 192 DrivingDirection_Q 100;
BA_REL_ "GenSigTimeoutTime" BU_SG_REL_ HAD3971 SG_ 192 DrivingDirection_Q 100;
BA_REL_ "GenSigTimeoutTime" BU_SG_REL_ VDC821 SG_ 192 BrakeTorqueOnWheels 100;
BA_REL_ "GenSigTimeoutTime" BU_SG_REL_ VDC397 SG_ 192 BrakeTorqueOnWheels 100;
BA_REL_ "GenSigTimeoutTime" BU_SG_REL_ VDC821 SG_ 192 EstimatedWheelPressure_FL 100;
BA_REL_ "GenSigTimeoutTime" BU_SG_REL_ VDC397 SG_ 192 EstimatedWheelPressure_FL 100;
BA_REL_ "GenSigTimeoutTime" BU_SG_REL_ PDCR SG_ 192 EstimatedWheelPressure_FL 100;
BA_REL_ "GenSigTimeoutTime" BU_SG_REL_ VDC821 SG_ 192 EstimatedWheelPressure_FR 100;
BA_REL_ "GenSigTimeoutTime" BU_SG_REL_ VDC397 SG_ 192 EstimatedWheelPressure_FR 100;
BA_REL_ "GenSigTimeoutTime" BU_SG_REL_ PDCR SG_ 192 EstimatedWheelPressure_FR 100;
BA_REL_ "GenSigTimeoutTime" BU_SG_REL_ VDC821 SG_ 192 EstimatedWheelPressure_RL 100;
BA_REL_ "GenSigTimeoutTime" BU_SG_REL_ VDC397 SG_ 192 EstimatedWheelPressure_RL 100;
BA_REL_ "GenSigTimeoutTime" BU_SG_REL_ PDCR SG_ 192 EstimatedWheelPressure_RL 100;
BA_REL_ "GenSigTimeoutTime" BU_SG_REL_ VDC821 SG_ 192 EstimatedWheelPressure_RR 100;
BA_REL_ "GenSigTimeoutTime" BU_SG_REL_ VDC397 SG_ 192 EstimatedWheelPressure_RR 100;
BA_REL_ "GenSigTimeoutTime" BU_SG_REL_ PDCR SG_ 192 EstimatedWheelPressure_RR 100;
BA_REL_ "GenSigTimeoutTime" BU_SG_REL_ VDC821 SG_ 192 LiveCounter_ABS_1 100;
BA_REL_ "GenSigTimeoutTime" BU_SG_REL_ VDC397 SG_ 192 LiveCounter_ABS_1 100;
BA_REL_ "GenSigTimeoutTime" BU_SG_REL_ HAD3971 SG_ 192 LiveCounter_ABS_1 100;
BA_REL_ "GenSigTimeoutTime" BU_SG_REL_ PDCM SG_ 192 LiveCounter_ABS_1 100;
BA_REL_ "GenSigTimeoutTime" BU_SG_REL_ PDCR SG_ 192 LiveCounter_ABS_1 100;
BA_REL_ "GenSigTimeoutTime" BU_SG_REL_ VDC821 SG_ 206 Checksum_EPBMaster_1 100;
BA_REL_ "GenSigTimeoutTime" BU_SG_REL_ VDC397 SG_ 206 Checksum_EPBMaster_1 100;
BA_REL_ "GenSigTimeoutTime" BU_SG_REL_ HAD3971 SG_ 206 Checksum_EPBMaster_1 100;
BA_REL_ "GenSigTimeoutTime" BU_SG_REL_ PDCM SG_ 206 Checksum_EPBMaster_1 100;
BA_REL_ "GenSigTimeoutTime" BU_SG_REL_ CSC SG_ 206 Checksum_EPBMaster_1 100;
BA_REL_ "GenSigTimeoutTime" BU_SG_REL_ PDCM SG_ 206 EPBMaster_Switch_1 100;
BA_REL_ "GenSigTimeoutTime" BU_SG_REL_ PDCM SG_ 206 RWU_Active_Master 100;
BA_REL_ "GenSigTimeoutTime" BU_SG_REL_ PDCM SG_ 206 SRU_Active_Master 100;
BA_REL_ "GenSigTimeoutTime" BU_SG_REL_ PDCM SG_ 206 LampCmd_EPBMaster_1 100;
BA_REL_ "GenSigTimeoutTime" BU_SG_REL_ CSC SG_ 206 LampCmd_EPBMaster_1 100;
BA_REL_ "GenSigTimeoutTime" BU_SG_REL_ PDCM SG_ 206 BrakeForceNotEnoughWarning_EPBMa 100;
BA_REL_ "GenSigTimeoutTime" BU_SG_REL_ PDCM SG_ 206 GradientHighWarning_EPBMaster_1 100;
BA_REL_ "GenSigTimeoutTime" BU_SG_REL_ PDCM SG_ 206 EPBMasterDecelerationRequest 100;
BA_REL_ "GenSigTimeoutTime" BU_SG_REL_ PDCM SG_ 206 StatusEPBMasterDecelerationReque 100;
BA_REL_ "GenSigTimeoutTime" BU_SG_REL_ VDC821 SG_ 206 BrakeLightCtrlCmd_EPBMaster_1 100;
BA_REL_ "GenSigTimeoutTime" BU_SG_REL_ VDC397 SG_ 206 BrakeLightCtrlCmd_EPBMaster_1 100;
BA_REL_ "GenSigTimeoutTime" BU_SG_REL_ PDCM SG_ 206 BrakeLightCtrlCmd_EPBMaster_1 100;
BA_REL_ "GenSigTimeoutTime" BU_SG_REL_ VDC821 SG_ 206 WorkingSt_EPBMaster_1 100;
BA_REL_ "GenSigTimeoutTime" BU_SG_REL_ VDC397 SG_ 206 WorkingSt_EPBMaster_1 100;
BA_REL_ "GenSigTimeoutTime" BU_SG_REL_ HAD3971 SG_ 206 WorkingSt_EPBMaster_1 100;
BA_REL_ "GenSigTimeoutTime" BU_SG_REL_ PDCM SG_ 206 WorkingSt_EPBMaster_1 100;
BA_REL_ "GenSigTimeoutTime" BU_SG_REL_ PDCR SG_ 206 WorkingSt_EPBMaster_1 100;
BA_REL_ "GenSigTimeoutTime" BU_SG_REL_ CSC SG_ 206 WorkingSt_EPBMaster_1 100;
BA_REL_ "GenSigTimeoutTime" BU_SG_REL_ PDCM SG_ 206 EPBMaster_TipInformation_1 100;
BA_REL_ "GenSigTimeoutTime" BU_SG_REL_ PDCM SG_ 206 AutoLockFunctionSt_EPBMaster_1 100;
BA_REL_ "GenSigTimeoutTime" BU_SG_REL_ PDCM SG_ 206 BrakeOverHeat_EPBMaster_1 100;
BA_REL_ "GenSigTimeoutTime" BU_SG_REL_ VDC821 SG_ 206 ErrorSt_EPBMaster_1 100;
BA_REL_ "GenSigTimeoutTime" BU_SG_REL_ VDC397 SG_ 206 ErrorSt_EPBMaster_1 100;
BA_REL_ "GenSigTimeoutTime" BU_SG_REL_ HAD3971 SG_ 206 ErrorSt_EPBMaster_1 100;
BA_REL_ "GenSigTimeoutTime" BU_SG_REL_ PDCM SG_ 206 ErrorSt_EPBMaster_1 100;
BA_REL_ "GenSigTimeoutTime" BU_SG_REL_ VDC821 SG_ 206 LiveCounter_EPBMaster_1 100;
BA_REL_ "GenSigTimeoutTime" BU_SG_REL_ VDC397 SG_ 206 LiveCounter_EPBMaster_1 100;
BA_REL_ "GenSigTimeoutTime" BU_SG_REL_ PDCM SG_ 206 LiveCounter_EPBMaster_1 100;
BA_REL_ "GenSigTimeoutTime" BU_SG_REL_ CSC SG_ 206 LiveCounter_EPBMaster_1 100;
BA_REL_ "GenSigTimeoutTime" BU_SG_REL_ VDC821 SG_ 208 Checksum_EPS1_SAS_1 100;
BA_REL_ "GenSigTimeoutTime" BU_SG_REL_ VDC397 SG_ 208 Checksum_EPS1_SAS_1 100;
BA_REL_ "GenSigTimeoutTime" BU_SG_REL_ HAD3971 SG_ 208 Checksum_EPS1_SAS_1 100;
BA_REL_ "GenSigTimeoutTime" BU_SG_REL_ PDCM SG_ 208 Checksum_EPS1_SAS_1 100;
BA_REL_ "GenSigTimeoutTime" BU_SG_REL_ PDCR SG_ 208 Checksum_EPS1_SAS_1 100;
BA_REL_ "GenSigTimeoutTime" BU_SG_REL_ VDC821 SG_ 208 EPS1_SteeringWheelAngle 100;
BA_REL_ "GenSigTimeoutTime" BU_SG_REL_ VDC397 SG_ 208 EPS1_SteeringWheelAngle 100;
BA_REL_ "GenSigTimeoutTime" BU_SG_REL_ HAD3971 SG_ 208 EPS1_SteeringWheelAngle 100;
BA_REL_ "GenSigTimeoutTime" BU_SG_REL_ PDCM SG_ 208 EPS1_SteeringWheelAngle 100;
BA_REL_ "GenSigTimeoutTime" BU_SG_REL_ PDCR SG_ 208 EPS1_SteeringWheelAngle 100;
BA_REL_ "GenSigTimeoutTime" BU_SG_REL_ VDC821 SG_ 208 EPS1_SteeringWheelAngleSign 100;
BA_REL_ "GenSigTimeoutTime" BU_SG_REL_ VDC397 SG_ 208 EPS1_SteeringWheelAngleSign 100;
BA_REL_ "GenSigTimeoutTime" BU_SG_REL_ HAD3971 SG_ 208 EPS1_SteeringWheelAngleSign 100;
BA_REL_ "GenSigTimeoutTime" BU_SG_REL_ PDCR SG_ 208 EPS1_SteeringWheelAngleSign 100;
BA_REL_ "GenSigTimeoutTime" BU_SG_REL_ VDC821 SG_ 208 EPS1_SteeringWheelSpeed 100;
BA_REL_ "GenSigTimeoutTime" BU_SG_REL_ VDC397 SG_ 208 EPS1_SteeringWheelSpeed 100;
BA_REL_ "GenSigTimeoutTime" BU_SG_REL_ HAD3971 SG_ 208 EPS1_SteeringWheelSpeed 100;
BA_REL_ "GenSigTimeoutTime" BU_SG_REL_ PDCR SG_ 208 EPS1_SteeringWheelSpeed 100;
BA_REL_ "GenSigTimeoutTime" BU_SG_REL_ VDC821 SG_ 208 EPS1_SteeringWheelSpeedSign 100;
BA_REL_ "GenSigTimeoutTime" BU_SG_REL_ VDC397 SG_ 208 EPS1_SteeringWheelSpeedSign 100;
BA_REL_ "GenSigTimeoutTime" BU_SG_REL_ HAD3971 SG_ 208 EPS1_SteeringWheelSpeedSign 100;
BA_REL_ "GenSigTimeoutTime" BU_SG_REL_ PDCR SG_ 208 EPS1_SteeringWheelSpeedSign 100;
BA_REL_ "GenSigTimeoutTime" BU_SG_REL_ VDC821 SG_ 208 EPS1_SAS_St 100;
BA_REL_ "GenSigTimeoutTime" BU_SG_REL_ VDC397 SG_ 208 EPS1_SAS_St 100;
BA_REL_ "GenSigTimeoutTime" BU_SG_REL_ HAD3971 SG_ 208 EPS1_SAS_St 100;
BA_REL_ "GenSigTimeoutTime" BU_SG_REL_ PDCR SG_ 208 EPS1_SAS_St 100;
BA_REL_ "GenSigTimeoutTime" BU_SG_REL_ VDC821 SG_ 208 LiveCounter_EPS1_SAS_1 100;
BA_REL_ "GenSigTimeoutTime" BU_SG_REL_ VDC397 SG_ 208 LiveCounter_EPS1_SAS_1 100;
BA_REL_ "GenSigTimeoutTime" BU_SG_REL_ HAD3971 SG_ 208 LiveCounter_EPS1_SAS_1 100;
BA_REL_ "GenSigTimeoutTime" BU_SG_REL_ PDCM SG_ 208 LiveCounter_EPS1_SAS_1 100;
BA_REL_ "GenSigTimeoutTime" BU_SG_REL_ PDCR SG_ 208 LiveCounter_EPS1_SAS_1 100;
BA_REL_ "GenSigTimeoutTime" BU_SG_REL_ VDC821 SG_ 336 Checksum_EPS_1_1 200;
BA_REL_ "GenSigTimeoutTime" BU_SG_REL_ VDC397 SG_ 336 Checksum_EPS_1_1 200;
BA_REL_ "GenSigTimeoutTime" BU_SG_REL_ HAD3971 SG_ 336 Checksum_EPS_1_1 200;
BA_REL_ "GenSigTimeoutTime" BU_SG_REL_ VDC821 SG_ 336 EPS_1_HandSteeringTorque 200;
BA_REL_ "GenSigTimeoutTime" BU_SG_REL_ VDC397 SG_ 336 EPS_1_HandSteeringTorque 200;
BA_REL_ "GenSigTimeoutTime" BU_SG_REL_ HAD3971 SG_ 336 EPS_1_HandSteeringTorque 200;
BA_REL_ "GenSigTimeoutTime" BU_SG_REL_ VDC821 SG_ 336 EPS_1_HandSteeringTorqueSign 200;
BA_REL_ "GenSigTimeoutTime" BU_SG_REL_ VDC397 SG_ 336 EPS_1_HandSteeringTorqueSign 200;
BA_REL_ "GenSigTimeoutTime" BU_SG_REL_ HAD3971 SG_ 336 EPS_1_HandSteeringTorqueSign 200;
BA_REL_ "GenSigTimeoutTime" BU_SG_REL_ VDC821 SG_ 336 EPS_1_ErrorStatus 200;
BA_REL_ "GenSigTimeoutTime" BU_SG_REL_ VDC397 SG_ 336 EPS_1_ErrorStatus 200;
BA_REL_ "GenSigTimeoutTime" BU_SG_REL_ HAD3971 SG_ 336 EPS_1_ErrorStatus 200;
BA_REL_ "GenSigTimeoutTime" BU_SG_REL_ VDC821 SG_ 336 EPS_1_ModeChangeEnable 200;
BA_REL_ "GenSigTimeoutTime" BU_SG_REL_ VDC397 SG_ 336 EPS_1_ModeChangeEnable 200;
BA_REL_ "GenSigTimeoutTime" BU_SG_REL_ VDC821 SG_ 336 EPS_1_HandOffStatus 200;
BA_REL_ "GenSigTimeoutTime" BU_SG_REL_ VDC397 SG_ 336 EPS_1_HandOffStatus 200;
BA_REL_ "GenSigTimeoutTime" BU_SG_REL_ HAD3971 SG_ 336 EPS_1_HandOffStatus 200;
BA_REL_ "GenSigTimeoutTime" BU_SG_REL_ VDC821 SG_ 336 EPS_1_HandOffValid 200;
BA_REL_ "GenSigTimeoutTime" BU_SG_REL_ VDC397 SG_ 336 EPS_1_HandOffValid 200;
BA_REL_ "GenSigTimeoutTime" BU_SG_REL_ HAD3971 SG_ 336 EPS_1_HandOffValid 200;
BA_REL_ "GenSigTimeoutTime" BU_SG_REL_ VDC821 SG_ 336 EPS_1_LKAStatus 200;
BA_REL_ "GenSigTimeoutTime" BU_SG_REL_ VDC397 SG_ 336 EPS_1_LKAStatus 200;
BA_REL_ "GenSigTimeoutTime" BU_SG_REL_ VDC821 SG_ 336 EPS_1_A_TASSensorStatus 200;
BA_REL_ "GenSigTimeoutTime" BU_SG_REL_ VDC397 SG_ 336 EPS_1_A_TASSensorStatus 200;
BA_REL_ "GenSigTimeoutTime" BU_SG_REL_ VDC821 SG_ 336 EPS_1_B_TASSensorStatus 200;
BA_REL_ "GenSigTimeoutTime" BU_SG_REL_ VDC397 SG_ 336 EPS_1_B_TASSensorStatus 200;
BA_REL_ "GenSigTimeoutTime" BU_SG_REL_ VDC821 SG_ 336 EPS_1_OverlayInputTorque 200;
BA_REL_ "GenSigTimeoutTime" BU_SG_REL_ VDC397 SG_ 336 EPS_1_OverlayInputTorque 200;
BA_REL_ "GenSigTimeoutTime" BU_SG_REL_ HAD3971 SG_ 336 EPS_1_OverlayInputTorque 200;
BA_REL_ "GenSigTimeoutTime" BU_SG_REL_ VDC821 SG_ 336 EPS_1_OverlayInputTorqueSign 200;
BA_REL_ "GenSigTimeoutTime" BU_SG_REL_ VDC397 SG_ 336 EPS_1_OverlayInputTorqueSign 200;
BA_REL_ "GenSigTimeoutTime" BU_SG_REL_ HAD3971 SG_ 336 EPS_1_OverlayInputTorqueSign 200;
BA_REL_ "GenSigTimeoutTime" BU_SG_REL_ VDC821 SG_ 336 EPS_1_AbortFeedback 200;
BA_REL_ "GenSigTimeoutTime" BU_SG_REL_ VDC397 SG_ 336 EPS_1_AbortFeedback 200;
BA_REL_ "GenSigTimeoutTime" BU_SG_REL_ HAD3971 SG_ 336 EPS_1_AbortFeedback 200;
BA_REL_ "GenSigTimeoutTime" BU_SG_REL_ VDC821 SG_ 336 EPS_1_WorkingMode_DMS 200;
BA_REL_ "GenSigTimeoutTime" BU_SG_REL_ VDC397 SG_ 336 EPS_1_WorkingMode_DMS 200;
BA_REL_ "GenSigTimeoutTime" BU_SG_REL_ VDC821 SG_ 336 LiveCounter_EPS_1_1 200;
BA_REL_ "GenSigTimeoutTime" BU_SG_REL_ VDC397 SG_ 336 LiveCounter_EPS_1_1 200;
BA_REL_ "GenSigTimeoutTime" BU_SG_REL_ VDC821 SG_ 337 Checksum_EPS_1_2 200;
BA_REL_ "GenSigTimeoutTime" BU_SG_REL_ VDC397 SG_ 337 Checksum_EPS_1_2 200;
BA_REL_ "GenSigTimeoutTime" BU_SG_REL_ HAD3971 SG_ 337 Checksum_EPS_1_2 200;
BA_REL_ "GenSigTimeoutTime" BU_SG_REL_ VDC821 SG_ 337 EPS_1_SACCStatus 200;
BA_REL_ "GenSigTimeoutTime" BU_SG_REL_ VDC397 SG_ 337 EPS_1_SACCStatus 200;
BA_REL_ "GenSigTimeoutTime" BU_SG_REL_ VDC821 SG_ 337 EPS_1_NOPStatus 200;
BA_REL_ "GenSigTimeoutTime" BU_SG_REL_ VDC397 SG_ 337 EPS_1_NOPStatus 200;
BA_REL_ "GenSigTimeoutTime" BU_SG_REL_ HAD3971 SG_ 337 EPS_1_NOPStatus 200;
BA_REL_ "GenSigTimeoutTime" BU_SG_REL_ VDC821 SG_ 337 EPS_1_NGPStatus 200;
BA_REL_ "GenSigTimeoutTime" BU_SG_REL_ VDC397 SG_ 337 EPS_1_NGPStatus 200;
BA_REL_ "GenSigTimeoutTime" BU_SG_REL_ VDC821 SG_ 337 EPS_1_APAStatus 200;
BA_REL_ "GenSigTimeoutTime" BU_SG_REL_ VDC397 SG_ 337 EPS_1_APAStatus 200;
BA_REL_ "GenSigTimeoutTime" BU_SG_REL_ VDC821 SG_ 337 EPS_1_RPAStatus 200;
BA_REL_ "GenSigTimeoutTime" BU_SG_REL_ VDC397 SG_ 337 EPS_1_RPAStatus 200;
BA_REL_ "GenSigTimeoutTime" BU_SG_REL_ VDC821 SG_ 337 EPS_1_AVPStatus 200;
BA_REL_ "GenSigTimeoutTime" BU_SG_REL_ VDC397 SG_ 337 EPS_1_AVPStatus 200;
BA_REL_ "GenSigTimeoutTime" BU_SG_REL_ VDC821 SG_ 337 EPS_1_EMAStatus 200;
BA_REL_ "GenSigTimeoutTime" BU_SG_REL_ VDC397 SG_ 337 EPS_1_EMAStatus 200;
BA_REL_ "GenSigTimeoutTime" BU_SG_REL_ VDC821 SG_ 337 EPS_1_DegradeLevel_HAD 200;
BA_REL_ "GenSigTimeoutTime" BU_SG_REL_ VDC397 SG_ 337 EPS_1_DegradeLevel_HAD 200;
BA_REL_ "GenSigTimeoutTime" BU_SG_REL_ HAD3971 SG_ 337 EPS_1_DegradeLevel_HAD 200;
BA_REL_ "GenSigTimeoutTime" BU_SG_REL_ VDC821 SG_ 337 EPS_1_PullingReminder 200;
BA_REL_ "GenSigTimeoutTime" BU_SG_REL_ VDC397 SG_ 337 EPS_1_PullingReminder 200;
BA_REL_ "GenSigTimeoutTime" BU_SG_REL_ HAD3971 SG_ 337 EPS_1_PullingReminder 200;
BA_REL_ "GenSigTimeoutTime" BU_SG_REL_ VDC821 SG_ 337 EPS_1_AutoDrivingMode 200;
BA_REL_ "GenSigTimeoutTime" BU_SG_REL_ VDC397 SG_ 337 EPS_1_AutoDrivingMode 200;
BA_REL_ "GenSigTimeoutTime" BU_SG_REL_ HAD3971 SG_ 337 EPS_1_AutoDrivingMode 200;
BA_REL_ "GenSigTimeoutTime" BU_SG_REL_ VDC821 SG_ 337 EPS_1_PullingTorque 200;
BA_REL_ "GenSigTimeoutTime" BU_SG_REL_ VDC397 SG_ 337 EPS_1_PullingTorque 200;
BA_REL_ "GenSigTimeoutTime" BU_SG_REL_ HAD3971 SG_ 337 EPS_1_PullingTorque 200;
BA_REL_ "GenSigTimeoutTime" BU_SG_REL_ VDC821 SG_ 337 EPS_1_PullingTorqueSign 200;
BA_REL_ "GenSigTimeoutTime" BU_SG_REL_ VDC397 SG_ 337 EPS_1_PullingTorqueSign 200;
BA_REL_ "GenSigTimeoutTime" BU_SG_REL_ HAD3971 SG_ 337 EPS_1_PullingTorqueSign 200;
BA_REL_ "GenSigTimeoutTime" BU_SG_REL_ VDC821 SG_ 337 EPS_1_L3BackupStatus 200;
BA_REL_ "GenSigTimeoutTime" BU_SG_REL_ VDC397 SG_ 337 EPS_1_L3BackupStatus 200;
BA_REL_ "GenSigTimeoutTime" BU_SG_REL_ VDC821 SG_ 337 LiveCounter_EPS_1_2 200;
BA_REL_ "GenSigTimeoutTime" BU_SG_REL_ VDC397 SG_ 337 LiveCounter_EPS_1_2 200;
BA_REL_ "GenSigTimeoutTime" BU_SG_REL_ HAD3971 SG_ 337 LiveCounter_EPS_1_2 200;
BA_REL_ "GenSigTimeoutTime" BU_SG_REL_ VDC821 SG_ 195 Checksum_ESC_1_W 100;
BA_REL_ "GenSigTimeoutTime" BU_SG_REL_ VDC397 SG_ 195 Checksum_ESC_1_W 100;
BA_REL_ "GenSigTimeoutTime" BU_SG_REL_ PDCR SG_ 195 Checksum_ESC_1_W 100;
BA_REL_ "GenSigTimeoutTime" BU_SG_REL_ VDC821 SG_ 195 TorqueReductionFast_TCS_FrontWhe 100;
BA_REL_ "GenSigTimeoutTime" BU_SG_REL_ VDC397 SG_ 195 TorqueReductionFast_TCS_FrontWhe 100;
BA_REL_ "GenSigTimeoutTime" BU_SG_REL_ VDC821 SG_ 195 TorqueIncrease_MSR_FrontWheel 100;
BA_REL_ "GenSigTimeoutTime" BU_SG_REL_ VDC397 SG_ 195 TorqueIncrease_MSR_FrontWheel 100;
BA_REL_ "GenSigTimeoutTime" BU_SG_REL_ VDC821 SG_ 195 TorqueReductionFast_TCS_RearWhee 100;
BA_REL_ "GenSigTimeoutTime" BU_SG_REL_ VDC397 SG_ 195 TorqueReductionFast_TCS_RearWhee 100;
BA_REL_ "GenSigTimeoutTime" BU_SG_REL_ VDC821 SG_ 195 TorqueIncrease_MSR_RearWheel 100;
BA_REL_ "GenSigTimeoutTime" BU_SG_REL_ VDC397 SG_ 195 TorqueIncrease_MSR_RearWheel 100;
BA_REL_ "GenSigTimeoutTime" BU_SG_REL_ VDC821 SG_ 195 ESC_RegenerationTorqueRequest 100;
BA_REL_ "GenSigTimeoutTime" BU_SG_REL_ VDC397 SG_ 195 ESC_RegenerationTorqueRequest 100;
BA_REL_ "GenSigTimeoutTime" BU_SG_REL_ VDC821 SG_ 195 ESC_RegenerationTorqueRequest_Q 100;
BA_REL_ "GenSigTimeoutTime" BU_SG_REL_ VDC397 SG_ 195 ESC_RegenerationTorqueRequest_Q 100;
BA_REL_ "GenSigTimeoutTime" BU_SG_REL_ VDC821 SG_ 195 TorqReductionFastSt_TCS_FrontWhe 100;
BA_REL_ "GenSigTimeoutTime" BU_SG_REL_ VDC397 SG_ 195 TorqReductionFastSt_TCS_FrontWhe 100;
BA_REL_ "GenSigTimeoutTime" BU_SG_REL_ VDC821 SG_ 195 TorqueIncreaseSt_MSR_FrontWheel 100;
BA_REL_ "GenSigTimeoutTime" BU_SG_REL_ VDC397 SG_ 195 TorqueIncreaseSt_MSR_FrontWheel 100;
BA_REL_ "GenSigTimeoutTime" BU_SG_REL_ VDC821 SG_ 195 TorqReductionFastSt_TCS_RearWhee 100;
BA_REL_ "GenSigTimeoutTime" BU_SG_REL_ VDC397 SG_ 195 TorqReductionFastSt_TCS_RearWhee 100;
BA_REL_ "GenSigTimeoutTime" BU_SG_REL_ VDC821 SG_ 195 TorqueIncreaseSt_MSR_RearWheel 100;
BA_REL_ "GenSigTimeoutTime" BU_SG_REL_ VDC397 SG_ 195 TorqueIncreaseSt_MSR_RearWheel 100;
BA_REL_ "GenSigTimeoutTime" BU_SG_REL_ PDCR SG_ 195 TorqueIncreaseSt_MSR_RearWheel 100;
BA_REL_ "GenSigTimeoutTime" BU_SG_REL_ VDC821 SG_ 195 ESC_StatusRegenerationTorqueRequ 100;
BA_REL_ "GenSigTimeoutTime" BU_SG_REL_ VDC397 SG_ 195 ESC_StatusRegenerationTorqueRequ 100;
BA_REL_ "GenSigTimeoutTime" BU_SG_REL_ VDC821 SG_ 195 ESC_FrontBiasMax 100;
BA_REL_ "GenSigTimeoutTime" BU_SG_REL_ VDC397 SG_ 195 ESC_FrontBiasMax 100;
BA_REL_ "GenSigTimeoutTime" BU_SG_REL_ VDC821 SG_ 195 ESC_RearBiasMax 100;
BA_REL_ "GenSigTimeoutTime" BU_SG_REL_ VDC397 SG_ 195 ESC_RearBiasMax 100;
BA_REL_ "GenSigTimeoutTime" BU_SG_REL_ VDC821 SG_ 195 LiveCounter_ESC_1_W 100;
BA_REL_ "GenSigTimeoutTime" BU_SG_REL_ VDC397 SG_ 195 LiveCounter_ESC_1_W 100;
BA_REL_ "GenSigTimeoutTime" BU_SG_REL_ PDCR SG_ 195 LiveCounter_ESC_1_W 100;
BA_REL_ "GenSigTimeoutTime" BU_SG_REL_ VDC821 SG_ 306 Checksum_ESC_2_1 100;
BA_REL_ "GenSigTimeoutTime" BU_SG_REL_ VDC397 SG_ 306 Checksum_ESC_2_1 100;
BA_REL_ "GenSigTimeoutTime" BU_SG_REL_ PDCM SG_ 306 Checksum_ESC_2_1 100;
BA_REL_ "GenSigTimeoutTime" BU_SG_REL_ PDCR SG_ 306 Checksum_ESC_2_1 100;
BA_REL_ "GenSigTimeoutTime" BU_SG_REL_ CSC SG_ 306 Checksum_ESC_2_1 100;
BA_REL_ "GenSigTimeoutTime" BU_SG_REL_ VDC821 SG_ 306 WorkingSt_ESC 100;
BA_REL_ "GenSigTimeoutTime" BU_SG_REL_ VDC397 SG_ 306 WorkingSt_ESC 100;
BA_REL_ "GenSigTimeoutTime" BU_SG_REL_ HAD3971 SG_ 306 WorkingSt_ESC 100;
BA_REL_ "GenSigTimeoutTime" BU_SG_REL_ PDCM SG_ 306 WorkingSt_ESC 100;
BA_REL_ "GenSigTimeoutTime" BU_SG_REL_ PDCR SG_ 306 WorkingSt_ESC 100;
BA_REL_ "GenSigTimeoutTime" BU_SG_REL_ VDC821 SG_ 306 ErrorSt_ESC 100;
BA_REL_ "GenSigTimeoutTime" BU_SG_REL_ VDC397 SG_ 306 ErrorSt_ESC 100;
BA_REL_ "GenSigTimeoutTime" BU_SG_REL_ HAD3971 SG_ 306 ErrorSt_ESC 100;
BA_REL_ "GenSigTimeoutTime" BU_SG_REL_ PDCM SG_ 306 ErrorSt_ESC 100;
BA_REL_ "GenSigTimeoutTime" BU_SG_REL_ PDCR SG_ 306 ErrorSt_ESC 100;
BA_REL_ "GenSigTimeoutTime" BU_SG_REL_ VDC821 SG_ 306 Intervention_ESC 100;
BA_REL_ "GenSigTimeoutTime" BU_SG_REL_ VDC397 SG_ 306 Intervention_ESC 100;
BA_REL_ "GenSigTimeoutTime" BU_SG_REL_ HAD3971 SG_ 306 Intervention_ESC 100;
BA_REL_ "GenSigTimeoutTime" BU_SG_REL_ PDCM SG_ 306 Intervention_ESC 100;
BA_REL_ "GenSigTimeoutTime" BU_SG_REL_ PDCR SG_ 306 Intervention_ESC 100;
BA_REL_ "GenSigTimeoutTime" BU_SG_REL_ VDC821 SG_ 306 ErrorSt_ABS 100;
BA_REL_ "GenSigTimeoutTime" BU_SG_REL_ VDC397 SG_ 306 ErrorSt_ABS 100;
BA_REL_ "GenSigTimeoutTime" BU_SG_REL_ HAD3971 SG_ 306 ErrorSt_ABS 100;
BA_REL_ "GenSigTimeoutTime" BU_SG_REL_ PDCM SG_ 306 ErrorSt_ABS 100;
BA_REL_ "GenSigTimeoutTime" BU_SG_REL_ PDCR SG_ 306 ErrorSt_ABS 100;
BA_REL_ "GenSigTimeoutTime" BU_SG_REL_ CSC SG_ 306 ErrorSt_ABS 100;
BA_REL_ "GenSigTimeoutTime" BU_SG_REL_ VDC821 SG_ 306 Intervention_ABS 100;
BA_REL_ "GenSigTimeoutTime" BU_SG_REL_ VDC397 SG_ 306 Intervention_ABS 100;
BA_REL_ "GenSigTimeoutTime" BU_SG_REL_ HAD3971 SG_ 306 Intervention_ABS 100;
BA_REL_ "GenSigTimeoutTime" BU_SG_REL_ PDCM SG_ 306 Intervention_ABS 100;
BA_REL_ "GenSigTimeoutTime" BU_SG_REL_ PDCR SG_ 306 Intervention_ABS 100;
BA_REL_ "GenSigTimeoutTime" BU_SG_REL_ VDC821 SG_ 306 ESC_Status_RollerBenchMode 100;
BA_REL_ "GenSigTimeoutTime" BU_SG_REL_ VDC397 SG_ 306 ESC_Status_RollerBenchMode 100;
BA_REL_ "GenSigTimeoutTime" BU_SG_REL_ VDC821 SG_ 306 Intervention_TCS 100;
BA_REL_ "GenSigTimeoutTime" BU_SG_REL_ VDC397 SG_ 306 Intervention_TCS 100;
BA_REL_ "GenSigTimeoutTime" BU_SG_REL_ HAD3971 SG_ 306 Intervention_TCS 100;
BA_REL_ "GenSigTimeoutTime" BU_SG_REL_ PDCM SG_ 306 Intervention_TCS 100;
BA_REL_ "GenSigTimeoutTime" BU_SG_REL_ PDCR SG_ 306 Intervention_TCS 100;
BA_REL_ "GenSigTimeoutTime" BU_SG_REL_ VDC821 SG_ 306 ErrorSt_EBD 100;
BA_REL_ "GenSigTimeoutTime" BU_SG_REL_ VDC397 SG_ 306 ErrorSt_EBD 100;
BA_REL_ "GenSigTimeoutTime" BU_SG_REL_ PDCM SG_ 306 ErrorSt_EBD 100;
BA_REL_ "GenSigTimeoutTime" BU_SG_REL_ PDCR SG_ 306 ErrorSt_EBD 100;
BA_REL_ "GenSigTimeoutTime" BU_SG_REL_ CSC SG_ 306 ErrorSt_EBD 100;
BA_REL_ "GenSigTimeoutTime" BU_SG_REL_ VDC821 SG_ 306 AvailableSt_CDP 100;
BA_REL_ "GenSigTimeoutTime" BU_SG_REL_ VDC397 SG_ 306 AvailableSt_CDP 100;
BA_REL_ "GenSigTimeoutTime" BU_SG_REL_ HAD3971 SG_ 306 AvailableSt_CDP 100;
BA_REL_ "GenSigTimeoutTime" BU_SG_REL_ PDCR SG_ 306 AvailableSt_CDP 100;
BA_REL_ "GenSigTimeoutTime" BU_SG_REL_ VDC821 SG_ 306 Intervention_CDP 100;
BA_REL_ "GenSigTimeoutTime" BU_SG_REL_ VDC397 SG_ 306 Intervention_CDP 100;
BA_REL_ "GenSigTimeoutTime" BU_SG_REL_ HAD3971 SG_ 306 Intervention_CDP 100;
BA_REL_ "GenSigTimeoutTime" BU_SG_REL_ VDC821 SG_ 306 AvailableSt_HHC 100;
BA_REL_ "GenSigTimeoutTime" BU_SG_REL_ VDC397 SG_ 306 AvailableSt_HHC 100;
BA_REL_ "GenSigTimeoutTime" BU_SG_REL_ VDC821 SG_ 306 Intervention_HHC 100;
BA_REL_ "GenSigTimeoutTime" BU_SG_REL_ VDC397 SG_ 306 Intervention_HHC 100;
BA_REL_ "GenSigTimeoutTime" BU_SG_REL_ VDC821 SG_ 306 AvailableSt_HDC 100;
BA_REL_ "GenSigTimeoutTime" BU_SG_REL_ VDC397 SG_ 306 AvailableSt_HDC 100;
BA_REL_ "GenSigTimeoutTime" BU_SG_REL_ HAD3971 SG_ 306 AvailableSt_HDC 100;
BA_REL_ "GenSigTimeoutTime" BU_SG_REL_ VDC821 SG_ 306 WorkingSt_HDC 100;
BA_REL_ "GenSigTimeoutTime" BU_SG_REL_ VDC397 SG_ 306 WorkingSt_HDC 100;
BA_REL_ "GenSigTimeoutTime" BU_SG_REL_ HAD3971 SG_ 306 WorkingSt_HDC 100;
BA_REL_ "GenSigTimeoutTime" BU_SG_REL_ VDC821 SG_ 306 ErrorSt_AVH 100;
BA_REL_ "GenSigTimeoutTime" BU_SG_REL_ VDC397 SG_ 306 ErrorSt_AVH 100;
BA_REL_ "GenSigTimeoutTime" BU_SG_REL_ HAD3971 SG_ 306 ErrorSt_AVH 100;
BA_REL_ "GenSigTimeoutTime" BU_SG_REL_ VDC821 SG_ 306 WorkingSt_AVH 100;
BA_REL_ "GenSigTimeoutTime" BU_SG_REL_ VDC397 SG_ 306 WorkingSt_AVH 100;
BA_REL_ "GenSigTimeoutTime" BU_SG_REL_ HAD3971 SG_ 306 WorkingSt_AVH 100;
BA_REL_ "GenSigTimeoutTime" BU_SG_REL_ PDCR SG_ 306 WorkingSt_AVH 100;
BA_REL_ "GenSigTimeoutTime" BU_SG_REL_ VDC821 SG_ 306 AvailableSt_AEB 100;
BA_REL_ "GenSigTimeoutTime" BU_SG_REL_ VDC397 SG_ 306 AvailableSt_AEB 100;
BA_REL_ "GenSigTimeoutTime" BU_SG_REL_ VDC821 SG_ 306 Intervention_AEB 100;
BA_REL_ "GenSigTimeoutTime" BU_SG_REL_ VDC397 SG_ 306 Intervention_AEB 100;
BA_REL_ "GenSigTimeoutTime" BU_SG_REL_ PDCM SG_ 306 Intervention_AEB 100;
BA_REL_ "GenSigTimeoutTime" BU_SG_REL_ VDC821 SG_ 306 AvailableSt_ABP 100;
BA_REL_ "GenSigTimeoutTime" BU_SG_REL_ VDC397 SG_ 306 AvailableSt_ABP 100;
BA_REL_ "GenSigTimeoutTime" BU_SG_REL_ VDC821 SG_ 306 Intervention_ABP 100;
BA_REL_ "GenSigTimeoutTime" BU_SG_REL_ VDC397 SG_ 306 Intervention_ABP 100;
BA_REL_ "GenSigTimeoutTime" BU_SG_REL_ VDC821 SG_ 306 AvailableSt_AWB 100;
BA_REL_ "GenSigTimeoutTime" BU_SG_REL_ VDC397 SG_ 306 AvailableSt_AWB 100;
BA_REL_ "GenSigTimeoutTime" BU_SG_REL_ VDC821 SG_ 306 Intervention_AWB 100;
BA_REL_ "GenSigTimeoutTime" BU_SG_REL_ VDC397 SG_ 306 Intervention_AWB 100;
BA_REL_ "GenSigTimeoutTime" BU_SG_REL_ VDC821 SG_ 306 AvailableSt_HBA 100;
BA_REL_ "GenSigTimeoutTime" BU_SG_REL_ VDC397 SG_ 306 AvailableSt_HBA 100;
BA_REL_ "GenSigTimeoutTime" BU_SG_REL_ VDC821 SG_ 306 Intervention_HBA 100;
BA_REL_ "GenSigTimeoutTime" BU_SG_REL_ VDC397 SG_ 306 Intervention_HBA 100;
BA_REL_ "GenSigTimeoutTime" BU_SG_REL_ VDC821 SG_ 306 Intervention_EmergencyBrake 100;
BA_REL_ "GenSigTimeoutTime" BU_SG_REL_ VDC397 SG_ 306 Intervention_EmergencyBrake 100;
BA_REL_ "GenSigTimeoutTime" BU_SG_REL_ VDC821 SG_ 306 VehicleStandstillSt_ESC 100;
BA_REL_ "GenSigTimeoutTime" BU_SG_REL_ VDC397 SG_ 306 VehicleStandstillSt_ESC 100;
BA_REL_ "GenSigTimeoutTime" BU_SG_REL_ HAD3971 SG_ 306 VehicleStandstillSt_ESC 100;
BA_REL_ "GenSigTimeoutTime" BU_SG_REL_ VDC821 SG_ 306 BrakeLightCtrlCmd_ESC 100;
BA_REL_ "GenSigTimeoutTime" BU_SG_REL_ VDC397 SG_ 306 BrakeLightCtrlCmd_ESC 100;
BA_REL_ "GenSigTimeoutTime" BU_SG_REL_ VDC821 SG_ 306 Intervention_BTCS_F 100;
BA_REL_ "GenSigTimeoutTime" BU_SG_REL_ VDC397 SG_ 306 Intervention_BTCS_F 100;
BA_REL_ "GenSigTimeoutTime" BU_SG_REL_ VDC821 SG_ 306 Intervention_BTCS_R 100;
BA_REL_ "GenSigTimeoutTime" BU_SG_REL_ VDC397 SG_ 306 Intervention_BTCS_R 100;
BA_REL_ "GenSigTimeoutTime" BU_SG_REL_ VDC821 SG_ 306 AvailableSt_MSR 100;
BA_REL_ "GenSigTimeoutTime" BU_SG_REL_ VDC397 SG_ 306 AvailableSt_MSR 100;
BA_REL_ "GenSigTimeoutTime" BU_SG_REL_ VDC821 SG_ 306 RoughRoadLevel 100;
BA_REL_ "GenSigTimeoutTime" BU_SG_REL_ VDC397 SG_ 306 RoughRoadLevel 100;
BA_REL_ "GenSigTimeoutTime" BU_SG_REL_ PDCM SG_ 306 RoughRoadLevel 100;
BA_REL_ "GenSigTimeoutTime" BU_SG_REL_ VDC821 SG_ 306 BrakeHoldActive 100;
BA_REL_ "GenSigTimeoutTime" BU_SG_REL_ VDC397 SG_ 306 BrakeHoldActive 100;
BA_REL_ "GenSigTimeoutTime" BU_SG_REL_ VDC821 SG_ 306 ParkingRequestToEPB 100;
BA_REL_ "GenSigTimeoutTime" BU_SG_REL_ VDC397 SG_ 306 ParkingRequestToEPB 100;
BA_REL_ "GenSigTimeoutTime" BU_SG_REL_ PDCR SG_ 306 ParkingRequestToEPB 100;
BA_REL_ "GenSigTimeoutTime" BU_SG_REL_ VDC821 SG_ 306 WorkingMode_ESC 100;
BA_REL_ "GenSigTimeoutTime" BU_SG_REL_ VDC397 SG_ 306 WorkingMode_ESC 100;
BA_REL_ "GenSigTimeoutTime" BU_SG_REL_ VDC821 SG_ 306 ModeChangeEnable_ESC 100;
BA_REL_ "GenSigTimeoutTime" BU_SG_REL_ VDC397 SG_ 306 ModeChangeEnable_ESC 100;
BA_REL_ "GenSigTimeoutTime" BU_SG_REL_ VDC821 SG_ 306 WorkingSt_CST 100;
BA_REL_ "GenSigTimeoutTime" BU_SG_REL_ VDC397 SG_ 306 WorkingSt_CST 100;
BA_REL_ "GenSigTimeoutTime" BU_SG_REL_ VDC821 SG_ 306 LiveCounter_ESC_2_1 100;
BA_REL_ "GenSigTimeoutTime" BU_SG_REL_ VDC397 SG_ 306 LiveCounter_ESC_2_1 100;
BA_REL_ "GenSigTimeoutTime" BU_SG_REL_ PDCM SG_ 306 LiveCounter_ESC_2_1 100;
BA_REL_ "GenSigTimeoutTime" BU_SG_REL_ PDCR SG_ 306 LiveCounter_ESC_2_1 100;
BA_REL_ "GenSigTimeoutTime" BU_SG_REL_ CSC SG_ 306 LiveCounter_ESC_2_1 100;
BA_REL_ "GenSigTimeoutTime" BU_SG_REL_ VDC821 SG_ 312 Checksum_ESC_5_1 200;
BA_REL_ "GenSigTimeoutTime" BU_SG_REL_ VDC397 SG_ 312 Checksum_ESC_5_1 200;
BA_REL_ "GenSigTimeoutTime" BU_SG_REL_ HAD3971 SG_ 312 Checksum_ESC_5_1 200;
BA_REL_ "GenSigTimeoutTime" BU_SG_REL_ VDC821 SG_ 312 ESC_TorqueReq_VMC_1 200;
BA_REL_ "GenSigTimeoutTime" BU_SG_REL_ VDC397 SG_ 312 ESC_TorqueReq_VMC_1 200;
BA_REL_ "GenSigTimeoutTime" BU_SG_REL_ VDC821 SG_ 312 ESC_TorqueReqSt_VMC_1 200;
BA_REL_ "GenSigTimeoutTime" BU_SG_REL_ VDC397 SG_ 312 ESC_TorqueReqSt_VMC_1 200;
BA_REL_ "GenSigTimeoutTime" BU_SG_REL_ VDC821 SG_ 312 ESC_TargetGearReq_VMC_1 200;
BA_REL_ "GenSigTimeoutTime" BU_SG_REL_ VDC397 SG_ 312 ESC_TargetGearReq_VMC_1 200;
BA_REL_ "GenSigTimeoutTime" BU_SG_REL_ VDC821 SG_ 312 ESC_TargetGearReqEnable_VMC_1 200;
BA_REL_ "GenSigTimeoutTime" BU_SG_REL_ VDC397 SG_ 312 ESC_TargetGearReqEnable_VMC_1 200;
BA_REL_ "GenSigTimeoutTime" BU_SG_REL_ VDC821 SG_ 312 ESC_SuspendStatus_L2 200;
BA_REL_ "GenSigTimeoutTime" BU_SG_REL_ VDC397 SG_ 312 ESC_SuspendStatus_L2 200;
BA_REL_ "GenSigTimeoutTime" BU_SG_REL_ VDC821 SG_ 312 ESC_EPBAvailableSt_L3 200;
BA_REL_ "GenSigTimeoutTime" BU_SG_REL_ VDC397 SG_ 312 ESC_EPBAvailableSt_L3 200;
BA_REL_ "GenSigTimeoutTime" BU_SG_REL_ HAD3971 SG_ 312 ESC_EPBAvailableSt_L3 200;
BA_REL_ "GenSigTimeoutTime" BU_SG_REL_ VDC821 SG_ 312 ESC_CommunicationSt_L3 200;
BA_REL_ "GenSigTimeoutTime" BU_SG_REL_ VDC397 SG_ 312 ESC_CommunicationSt_L3 200;
BA_REL_ "GenSigTimeoutTime" BU_SG_REL_ HAD3971 SG_ 312 ESC_CommunicationSt_L3 200;
BA_REL_ "GenSigTimeoutTime" BU_SG_REL_ VDC821 SG_ 312 ESC_UsedChannel_L3 200;
BA_REL_ "GenSigTimeoutTime" BU_SG_REL_ VDC397 SG_ 312 ESC_UsedChannel_L3 200;
BA_REL_ "GenSigTimeoutTime" BU_SG_REL_ HAD3971 SG_ 312 ESC_UsedChannel_L3 200;
BA_REL_ "GenSigTimeoutTime" BU_SG_REL_ VDC821 SG_ 312 ESC_ControllerReleaseSt_L3 200;
BA_REL_ "GenSigTimeoutTime" BU_SG_REL_ VDC397 SG_ 312 ESC_ControllerReleaseSt_L3 200;
BA_REL_ "GenSigTimeoutTime" BU_SG_REL_ HAD3971 SG_ 312 ESC_ControllerReleaseSt_L3 200;
BA_REL_ "GenSigTimeoutTime" BU_SG_REL_ VDC821 SG_ 312 ESC_SuspendStatusByDriver_L3 200;
BA_REL_ "GenSigTimeoutTime" BU_SG_REL_ VDC397 SG_ 312 ESC_SuspendStatusByDriver_L3 200;
BA_REL_ "GenSigTimeoutTime" BU_SG_REL_ HAD3971 SG_ 312 ESC_SuspendStatusByDriver_L3 200;
BA_REL_ "GenSigTimeoutTime" BU_SG_REL_ VDC821 SG_ 312 ESC_SuspendStatusByOther_L3 200;
BA_REL_ "GenSigTimeoutTime" BU_SG_REL_ VDC397 SG_ 312 ESC_SuspendStatusByOther_L3 200;
BA_REL_ "GenSigTimeoutTime" BU_SG_REL_ HAD3971 SG_ 312 ESC_SuspendStatusByOther_L3 200;
BA_REL_ "GenSigTimeoutTime" BU_SG_REL_ VDC821 SG_ 312 ESC_VLC_Error_L12 200;
BA_REL_ "GenSigTimeoutTime" BU_SG_REL_ VDC397 SG_ 312 ESC_VLC_Error_L12 200;
BA_REL_ "GenSigTimeoutTime" BU_SG_REL_ VDC821 SG_ 312 ESC_VLCSt 200;
BA_REL_ "GenSigTimeoutTime" BU_SG_REL_ VDC397 SG_ 312 ESC_VLCSt 200;
BA_REL_ "GenSigTimeoutTime" BU_SG_REL_ HAD3971 SG_ 312 ESC_VLCSt 200;
BA_REL_ "GenSigTimeoutTime" BU_SG_REL_ VDC821 SG_ 312 ESC_VMC_Error_L3 200;
BA_REL_ "GenSigTimeoutTime" BU_SG_REL_ VDC397 SG_ 312 ESC_VMC_Error_L3 200;
BA_REL_ "GenSigTimeoutTime" BU_SG_REL_ HAD3971 SG_ 312 ESC_VMC_Error_L3 200;
BA_REL_ "GenSigTimeoutTime" BU_SG_REL_ VDC821 SG_ 312 ESC_AutoDriving_LC_Brakemode 200;
BA_REL_ "GenSigTimeoutTime" BU_SG_REL_ VDC397 SG_ 312 ESC_AutoDriving_LC_Brakemode 200;
BA_REL_ "GenSigTimeoutTime" BU_SG_REL_ VDC821 SG_ 312 ESC_AutoPark_LC_HPA_Avail 200;
BA_REL_ "GenSigTimeoutTime" BU_SG_REL_ VDC397 SG_ 312 ESC_AutoPark_LC_HPA_Avail 200;
BA_REL_ "GenSigTimeoutTime" BU_SG_REL_ VDC821 SG_ 312 ESC_AutoPark_LCSt 200;
BA_REL_ "GenSigTimeoutTime" BU_SG_REL_ VDC397 SG_ 312 ESC_AutoPark_LCSt 200;
BA_REL_ "GenSigTimeoutTime" BU_SG_REL_ VDC821 SG_ 312 ESC_AutoPark_LC_APA_Avail 200;
BA_REL_ "GenSigTimeoutTime" BU_SG_REL_ VDC397 SG_ 312 ESC_AutoPark_LC_APA_Avail 200;
BA_REL_ "GenSigTimeoutTime" BU_SG_REL_ VDC821 SG_ 312 ESC_AutoPark_LC_RPA_Avail 200;
BA_REL_ "GenSigTimeoutTime" BU_SG_REL_ VDC397 SG_ 312 ESC_AutoPark_LC_RPA_Avail 200;
BA_REL_ "GenSigTimeoutTime" BU_SG_REL_ VDC821 SG_ 312 ESC_AutoPark_LC_AVP_Avail 200;
BA_REL_ "GenSigTimeoutTime" BU_SG_REL_ VDC397 SG_ 312 ESC_AutoPark_LC_AVP_Avail 200;
BA_REL_ "GenSigTimeoutTime" BU_SG_REL_ VDC821 SG_ 312 ESC_AutoPark_LCFailureSt 200;
BA_REL_ "GenSigTimeoutTime" BU_SG_REL_ VDC397 SG_ 312 ESC_AutoPark_LCFailureSt 200;
BA_REL_ "GenSigTimeoutTime" BU_SG_REL_ VDC821 SG_ 312 ESC_AutoPark_LC_BrakeMode 200;
BA_REL_ "GenSigTimeoutTime" BU_SG_REL_ VDC397 SG_ 312 ESC_AutoPark_LC_BrakeMode 200;
BA_REL_ "GenSigTimeoutTime" BU_SG_REL_ VDC821 SG_ 312 ESC_HDCActiveForbidden 200;
BA_REL_ "GenSigTimeoutTime" BU_SG_REL_ VDC397 SG_ 312 ESC_HDCActiveForbidden 200;
BA_REL_ "GenSigTimeoutTime" BU_SG_REL_ VDC821 SG_ 312 ESC_ESCOffForbidden 200;
BA_REL_ "GenSigTimeoutTime" BU_SG_REL_ VDC397 SG_ 312 ESC_ESCOffForbidden 200;
BA_REL_ "GenSigTimeoutTime" BU_SG_REL_ VDC821 SG_ 312 ESC_AVHActiveForbidden 200;
BA_REL_ "GenSigTimeoutTime" BU_SG_REL_ VDC397 SG_ 312 ESC_AVHActiveForbidden 200;
BA_REL_ "GenSigTimeoutTime" BU_SG_REL_ VDC821 SG_ 312 ESC_ShutOffFinished 200;
BA_REL_ "GenSigTimeoutTime" BU_SG_REL_ VDC397 SG_ 312 ESC_ShutOffFinished 200;
BA_REL_ "GenSigTimeoutTime" BU_SG_REL_ VDC821 SG_ 312 ESC_BrakePadelOverride 200;
BA_REL_ "GenSigTimeoutTime" BU_SG_REL_ VDC397 SG_ 312 ESC_BrakePadelOverride 200;
BA_REL_ "GenSigTimeoutTime" BU_SG_REL_ VDC821 SG_ 312 LiveCounter_ESC_5_1 200;
BA_REL_ "GenSigTimeoutTime" BU_SG_REL_ VDC397 SG_ 312 LiveCounter_ESC_5_1 200;
BA_REL_ "GenSigTimeoutTime" BU_SG_REL_ HAD3971 SG_ 312 LiveCounter_ESC_5_1 200;
BA_REL_ "GenSigTimeoutTime" BU_SG_REL_ VDC821 SG_ 193 Checksum_IBC_1 100;
BA_REL_ "GenSigTimeoutTime" BU_SG_REL_ VDC397 SG_ 193 Checksum_IBC_1 100;
BA_REL_ "GenSigTimeoutTime" BU_SG_REL_ HAD3971 SG_ 193 Checksum_IBC_1 100;
BA_REL_ "GenSigTimeoutTime" BU_SG_REL_ PDCR SG_ 193 Checksum_IBC_1 100;
BA_REL_ "GenSigTimeoutTime" BU_SG_REL_ VDC821 SG_ 193 IBC_SimulatorPressure 100;
BA_REL_ "GenSigTimeoutTime" BU_SG_REL_ VDC397 SG_ 193 IBC_SimulatorPressure 100;
BA_REL_ "GenSigTimeoutTime" BU_SG_REL_ HAD3971 SG_ 193 IBC_SimulatorPressure 100;
BA_REL_ "GenSigTimeoutTime" BU_SG_REL_ VDC821 SG_ 193 IBC_SimulatorPressureSt 100;
BA_REL_ "GenSigTimeoutTime" BU_SG_REL_ VDC397 SG_ 193 IBC_SimulatorPressureSt 100;
BA_REL_ "GenSigTimeoutTime" BU_SG_REL_ HAD3971 SG_ 193 IBC_SimulatorPressureSt 100;
BA_REL_ "GenSigTimeoutTime" BU_SG_REL_ VDC821 SG_ 193 IBC_SystemStatus 100;
BA_REL_ "GenSigTimeoutTime" BU_SG_REL_ VDC397 SG_ 193 IBC_SystemStatus 100;
BA_REL_ "GenSigTimeoutTime" BU_SG_REL_ VDC821 SG_ 193 IBC_PlungerPressure 100;
BA_REL_ "GenSigTimeoutTime" BU_SG_REL_ VDC397 SG_ 193 IBC_PlungerPressure 100;
BA_REL_ "GenSigTimeoutTime" BU_SG_REL_ HAD3971 SG_ 193 IBC_PlungerPressure 100;
BA_REL_ "GenSigTimeoutTime" BU_SG_REL_ PDCR SG_ 193 IBC_PlungerPressure 100;
BA_REL_ "GenSigTimeoutTime" BU_SG_REL_ VDC821 SG_ 193 IBC_PlungerPressureSt 100;
BA_REL_ "GenSigTimeoutTime" BU_SG_REL_ VDC397 SG_ 193 IBC_PlungerPressureSt 100;
BA_REL_ "GenSigTimeoutTime" BU_SG_REL_ HAD3971 SG_ 193 IBC_PlungerPressureSt 100;
BA_REL_ "GenSigTimeoutTime" BU_SG_REL_ PDCR SG_ 193 IBC_PlungerPressureSt 100;
BA_REL_ "GenSigTimeoutTime" BU_SG_REL_ VDC821 SG_ 193 IBC_BrakePedalStatus_Q 100;
BA_REL_ "GenSigTimeoutTime" BU_SG_REL_ VDC397 SG_ 193 IBC_BrakePedalStatus_Q 100;
BA_REL_ "GenSigTimeoutTime" BU_SG_REL_ HAD3971 SG_ 193 IBC_BrakePedalStatus_Q 100;
BA_REL_ "GenSigTimeoutTime" BU_SG_REL_ VDC821 SG_ 193 IBC_InputRodStroke 100;
BA_REL_ "GenSigTimeoutTime" BU_SG_REL_ VDC397 SG_ 193 IBC_InputRodStroke 100;
BA_REL_ "GenSigTimeoutTime" BU_SG_REL_ HAD3971 SG_ 193 IBC_InputRodStroke 100;
BA_REL_ "GenSigTimeoutTime" BU_SG_REL_ VDC821 SG_ 193 IBC_InputRodStrokeSt 100;
BA_REL_ "GenSigTimeoutTime" BU_SG_REL_ VDC397 SG_ 193 IBC_InputRodStrokeSt 100;
BA_REL_ "GenSigTimeoutTime" BU_SG_REL_ HAD3971 SG_ 193 IBC_InputRodStrokeSt 100;
BA_REL_ "GenSigTimeoutTime" BU_SG_REL_ VDC821 SG_ 193 IBC_BrakeFluidWarning 100;
BA_REL_ "GenSigTimeoutTime" BU_SG_REL_ VDC397 SG_ 193 IBC_BrakeFluidWarning 100;
BA_REL_ "GenSigTimeoutTime" BU_SG_REL_ VDC821 SG_ 193 IBC_BrakePedalStatus 100;
BA_REL_ "GenSigTimeoutTime" BU_SG_REL_ VDC397 SG_ 193 IBC_BrakePedalStatus 100;
BA_REL_ "GenSigTimeoutTime" BU_SG_REL_ HAD3971 SG_ 193 IBC_BrakePedalStatus 100;
BA_REL_ "GenSigTimeoutTime" BU_SG_REL_ VDC821 SG_ 193 TwoFootBrakeSt 100;
BA_REL_ "GenSigTimeoutTime" BU_SG_REL_ VDC397 SG_ 193 TwoFootBrakeSt 100;
BA_REL_ "GenSigTimeoutTime" BU_SG_REL_ VDC821 SG_ 193 DegradedBBFWarning 100;
BA_REL_ "GenSigTimeoutTime" BU_SG_REL_ VDC397 SG_ 193 DegradedBBFWarning 100;
BA_REL_ "GenSigTimeoutTime" BU_SG_REL_ VDC821 SG_ 193 FWAWarning 100;
BA_REL_ "GenSigTimeoutTime" BU_SG_REL_ VDC397 SG_ 193 FWAWarning 100;
BA_REL_ "GenSigTimeoutTime" BU_SG_REL_ VDC821 SG_ 193 IBC_RearWheelAngleRequest 100;
BA_REL_ "GenSigTimeoutTime" BU_SG_REL_ VDC397 SG_ 193 IBC_RearWheelAngleRequest 100;
BA_REL_ "GenSigTimeoutTime" BU_SG_REL_ VDC821 SG_ 193 IBC_RearWheelAngleRequestSt 100;
BA_REL_ "GenSigTimeoutTime" BU_SG_REL_ VDC397 SG_ 193 IBC_RearWheelAngleRequestSt 100;
BA_REL_ "GenSigTimeoutTime" BU_SG_REL_ VDC821 SG_ 193 IBC_VDCActive 100;
BA_REL_ "GenSigTimeoutTime" BU_SG_REL_ VDC397 SG_ 193 IBC_VDCActive 100;
BA_REL_ "GenSigTimeoutTime" BU_SG_REL_ VDC821 SG_ 193 LiveCounter_IBC_1 100;
BA_REL_ "GenSigTimeoutTime" BU_SG_REL_ VDC397 SG_ 193 LiveCounter_IBC_1 100;
BA_REL_ "GenSigTimeoutTime" BU_SG_REL_ HAD3971 SG_ 193 LiveCounter_IBC_1 100;
BA_REL_ "GenSigTimeoutTime" BU_SG_REL_ PDCR SG_ 193 LiveCounter_IBC_1 100;
BA_REL_ "GenSigTimeoutTime" BU_SG_REL_ VDC397 SG_ 1381 SECOC_FVReqCode_IBC 500;
BA_REL_ "GenSigTimeoutTime" BU_SG_REL_ VDC821 SG_ 554 LimphomeSt_FL 1000;
BA_REL_ "GenSigTimeoutTime" BU_SG_REL_ VDC821 SG_ 554 PositionLightSt_FL 1000;
BA_REL_ "GenSigTimeoutTime" BU_SG_REL_ VDC821 SG_ 554 DayRunningLightSt_FL 1000;
BA_REL_ "GenSigTimeoutTime" BU_SG_REL_ VDC821 SG_ 554 FogLightSt_FL 1000;
BA_REL_ "GenSigTimeoutTime" BU_SG_REL_ VDC821 SG_ 554 TurningSt_FL 1000;
BA_REL_ "GenSigTimeoutTime" BU_SG_REL_ VDC821 SG_ 554 TurningSt_LeftSide 1000;
BA_REL_ "GenSigTimeoutTime" BU_SG_REL_ VDC821 SG_ 554 ADSLightSt_FL 1000;
BA_REL_ "GenSigTimeoutTime" BU_SG_REL_ VDC821 SG_ 554 CeremonyModeStatus_FL 1000;
BA_REL_ "GenSigTimeoutTime" BU_SG_REL_ VDC821 SG_ 554 TurnLightFaultSt_LeftSide 1000;
BA_REL_ "GenSigTimeoutTime" BU_SG_REL_ VDC821 SG_ 554 HighBeamSt_FL 1000;
BA_REL_ "GenSigTimeoutTime" BU_SG_REL_ VDC821 SG_ 554 FoglightFaultSt_FL 1000;
BA_REL_ "GenSigTimeoutTime" BU_SG_REL_ VDC821 SG_ 554 HighbeamFaultSt_FL 1000;
BA_REL_ "GenSigTimeoutTime" BU_SG_REL_ VDC821 SG_ 554 PositionLightFaultSt_FL 1000;
BA_REL_ "GenSigTimeoutTime" BU_SG_REL_ VDC821 SG_ 554 DayRunningLightFaultSt_FL 1000;
BA_REL_ "GenSigTimeoutTime" BU_SG_REL_ VDC821 SG_ 554 TurningLightFaultSt_FL 1000;
BA_REL_ "GenSigTimeoutTime" BU_SG_REL_ VDC821 SG_ 554 ADSLightFaultSt_FL 1000;
BA_REL_ "GenSigTimeoutTime" BU_SG_REL_ VDC821 SG_ 554 CornerLampSt_FL 1000;
BA_REL_ "GenSigTimeoutTime" BU_SG_REL_ VDC821 SG_ 554 LampOTAMode_FL 1000;
BA_REL_ "GenSigTimeoutTime" BU_SG_REL_ VDC821 SG_ 554 CornerLampFaultSt_FL 1000;
BA_REL_ "GenSigTimeoutTime" BU_SG_REL_ VDC821 SG_ 554 ALS_Init_FL 1000;
BA_REL_ "GenSigTimeoutTime" BU_SG_REL_ VDC821 SG_ 554 ALS_MotorFault_FL 1000;
BA_REL_ "GenSigTimeoutTime" BU_SG_REL_ VDC821 SG_ 554 ALS_MotorPosition_FL 1000;
BA_REL_ "GenSigTimeoutTime" BU_SG_REL_ VDC821 SG_ 502 Checksum_LampFL_2 1000;
BA_REL_ "GenSigTimeoutTime" BU_SG_REL_ VDC821 SG_ 502 LowBeamSt_FL 1000;
BA_REL_ "GenSigTimeoutTime" BU_SG_REL_ VDC821 SG_ 502 LowbeamFaultSt_FL 1000;
BA_REL_ "GenSigTimeoutTime" BU_SG_REL_ VDC821 SG_ 502 LiveCounter_LampFL_2 1000;
BA_REL_ "GenSigTimeoutTime" BU_SG_REL_ VDC821 SG_ 810 LimphomeSt_FR 1000;
BA_REL_ "GenSigTimeoutTime" BU_SG_REL_ VDC821 SG_ 810 PositionLightSt_FR 1000;
BA_REL_ "GenSigTimeoutTime" BU_SG_REL_ VDC821 SG_ 810 DayRunningLightSt_FR 1000;
BA_REL_ "GenSigTimeoutTime" BU_SG_REL_ VDC821 SG_ 810 FogLightSt_FR 1000;
BA_REL_ "GenSigTimeoutTime" BU_SG_REL_ VDC821 SG_ 810 TurningSt_FR 1000;
BA_REL_ "GenSigTimeoutTime" BU_SG_REL_ VDC821 SG_ 810 TurningSt_RightSide 1000;
BA_REL_ "GenSigTimeoutTime" BU_SG_REL_ VDC821 SG_ 810 ADSLightSt_FR 1000;
BA_REL_ "GenSigTimeoutTime" BU_SG_REL_ VDC821 SG_ 810 CeremonyModeStatus_FR 1000;
BA_REL_ "GenSigTimeoutTime" BU_SG_REL_ VDC821 SG_ 810 TurnLightFaultSt_RightSide 1000;
BA_REL_ "GenSigTimeoutTime" BU_SG_REL_ VDC821 SG_ 810 HighBeamSt_FR 1000;
BA_REL_ "GenSigTimeoutTime" BU_SG_REL_ VDC821 SG_ 810 FoglightFaultSt_FR 1000;
BA_REL_ "GenSigTimeoutTime" BU_SG_REL_ VDC821 SG_ 810 HighbeamFaultSt_FR 1000;
BA_REL_ "GenSigTimeoutTime" BU_SG_REL_ VDC821 SG_ 810 PositionLightFaultSt_FR 1000;
BA_REL_ "GenSigTimeoutTime" BU_SG_REL_ VDC821 SG_ 810 DayRunningLightFaultSt_FR 1000;
BA_REL_ "GenSigTimeoutTime" BU_SG_REL_ VDC821 SG_ 810 TurningLightFaultSt_FR 1000;
BA_REL_ "GenSigTimeoutTime" BU_SG_REL_ VDC821 SG_ 810 ADSLightFaultSt_FR 1000;
BA_REL_ "GenSigTimeoutTime" BU_SG_REL_ VDC821 SG_ 810 CornerLampSt_FR 1000;
BA_REL_ "GenSigTimeoutTime" BU_SG_REL_ VDC821 SG_ 810 LampOTAMode_FR 1000;
BA_REL_ "GenSigTimeoutTime" BU_SG_REL_ VDC821 SG_ 810 CornerLampFaultSt_FR 1000;
BA_REL_ "GenSigTimeoutTime" BU_SG_REL_ VDC821 SG_ 810 ALS_Init_FR 1000;
BA_REL_ "GenSigTimeoutTime" BU_SG_REL_ VDC821 SG_ 810 ALS_MotorFault_FR 1000;
BA_REL_ "GenSigTimeoutTime" BU_SG_REL_ VDC821 SG_ 810 ALS_MotorPosition_FR 1000;
BA_REL_ "GenSigTimeoutTime" BU_SG_REL_ VDC821 SG_ 501 Checksum_LampFR_2 1000;
BA_REL_ "GenSigTimeoutTime" BU_SG_REL_ VDC821 SG_ 501 LowBeamSt_FR 1000;
BA_REL_ "GenSigTimeoutTime" BU_SG_REL_ VDC821 SG_ 501 LowbeamFaultSt_FR 1000;
BA_REL_ "GenSigTimeoutTime" BU_SG_REL_ VDC821 SG_ 501 LiveCounter_LampFR_2 1000;
BA_REL_ "GenSigTimeoutTime" BU_SG_REL_ VDC821 SG_ 1210 SoftwareNumber_EPS 50000;
BA_REL_ "GenSigTimeoutTime" BU_SG_REL_ VDC821 SG_ 1210 HardwareRelated_ConfigID_EPS 50000;
BA_REL_ "GenSigTimeoutTime" BU_SG_REL_ VDC821 SG_ 1260 SoftwareNumber_IBC 50000;
BA_REL_ "GenSigTimeoutTime" BU_SG_REL_ VDC821 SG_ 1260 HardwareRelated_ConfigID_IBC 50000;
BA_REL_ "GenSigTimeoutTime" BU_SG_REL_ VDC821 SG_ 1272 SoftwareNumber_MCUF 50000;
BA_REL_ "GenSigTimeoutTime" BU_SG_REL_ VDC821 SG_ 1272 HardwareRelated_ConfigID_MCUF 50000;
BA_REL_ "GenSigTimeoutTime" BU_SG_REL_ VDC821 SG_ 1193 SoftwareNumber_PDCF 50000;
BA_REL_ "GenSigTimeoutTime" BU_SG_REL_ VDC821 SG_ 1193 HardwareRelated_ConfigID_PDCF 50000;
BA_REL_ "GenSigTimeoutTime" BU_SG_REL_ VDC821 SG_ 1065 SoftwareNumber_PDCM 50000;
BA_REL_ "GenSigTimeoutTime" BU_SG_REL_ VDC821 SG_ 1065 HardwareRelated_ConfigID_PDCM 50000;
BA_REL_ "GenSigTimeoutTime" BU_SG_REL_ VDC821 SG_ 1199 SoftwareNumber_RBU 50000;
BA_REL_ "GenSigTimeoutTime" BU_SG_REL_ VDC821 SG_ 1199 HardwareRelated_ConfigID_RBU 50000;
BA_REL_ "GenSigTimeoutTime" BU_SG_REL_ VDC821 SG_ 1214 SoftwareNumber_RWS 50000;
BA_REL_ "GenSigTimeoutTime" BU_SG_REL_ VDC821 SG_ 1214 HardwareRelated_ConfigID_RWS 50000;
BA_REL_ "GenSigTimeoutTime" BU_SG_REL_ VDC821 SG_ 1037 SoftwareNumber_LAMP_FL 50000;
BA_REL_ "GenSigTimeoutTime" BU_SG_REL_ VDC821 SG_ 1037 HardwareRelated_ConfigID_LAMP_FL 50000;
BA_REL_ "GenSigTimeoutTime" BU_SG_REL_ VDC821 SG_ 1211 SoftwareNumber_LAMP_FR 50000;
BA_REL_ "GenSigTimeoutTime" BU_SG_REL_ VDC821 SG_ 1211 HardwareRelated_ConfigID_LAMP_FR 50000;
BA_REL_ "GenSigTimeoutTime" BU_SG_REL_ VDC821 SG_ 1215 SoftwareNumber_PNG1 50000;
BA_REL_ "GenSigTimeoutTime" BU_SG_REL_ VDC821 SG_ 1215 HardwareRelated_ConfigID_PNG1 50000;
BA_REL_ "GenSigTimeoutTime" BU_SG_REL_ VDC821 SG_ 1276 SoftwareNumber_PNG2 50000;
BA_REL_ "GenSigTimeoutTime" BU_SG_REL_ VDC821 SG_ 1276 HardwareRelated_ConfigID_PNG2 50000;
BA_REL_ "GenSigTimeoutTime" BU_SG_REL_ VDC397 SG_ 1377 SECOC_FVReqCode_PDCF 500;
VAL_ 192 WheelSpeed_FL 32767 "SNA" ;
VAL_ 192 WheelSpeed_FR 32767 "SNA" ;
VAL_ 192 WheelSpeed_RL 32767 "SNA" ;
VAL_ 192 WheelSpeed_RR 32767 "SNA" ;
VAL_ 192 WheelPulse_FL 255 "SNA" ;
VAL_ 192 WheelPulse_FR 255 "SNA" ;
VAL_ 192 WheelPulse_RL 255 "SNA" ;
VAL_ 192 WheelPulse_RR 255 "SNA" ;
VAL_ 192 WheelSpeedDirection_FL 3 "Undefined" 2 "Backward" 1 "Forward" 0 "Stop" ;
VAL_ 192 WheelSpeedDirection_FR 3 "Undefined" 2 "Backward" 1 "Forward" 0 "Stop" ;
VAL_ 192 WheelSpeedDirection_RL 3 "Undefined" 2 "Backward" 1 "Forward" 0 "Stop" ;
VAL_ 192 WheelSpeedDirection_RR 3 "Undefined" 2 "Backward" 1 "Forward" 0 "Stop" ;
VAL_ 192 WheelSpeedDirection_FL_Q 1 "Faulty" 0 "Normal" ;
VAL_ 192 WheelSpeedDirection_FR_Q 1 "Faulty" 0 "Normal" ;
VAL_ 192 WheelSpeedDirection_RL_Q 1 "Faulty" 0 "Normal" ;
VAL_ 192 WheelSpeedDirection_RR_Q 1 "Faulty" 0 "Normal" ;
VAL_ 192 VehicleSpeed 32767 "SNA" ;
VAL_ 192 VehiclSpeed_Q 1 "Faulty" 0 "Normal" ;
VAL_ 192 DrivingDirection 3 "Undefined" 2 "Backward" 1 "Forward" 0 "Stop" ;
VAL_ 192 DrivingDirection_Q 1 "Faulty" 0 "Normal" ;
VAL_ 192 BrakeTorqueOnWheels 4095 "SNA" ;
VAL_ 192 EstimatedWheelPressure_FL 16383 "SNA" ;
VAL_ 192 EstimatedWheelPressure_FR 16383 "SNA" ;
VAL_ 192 EstimatedWheelPressure_RL 16383 "SNA" ;
VAL_ 192 EstimatedWheelPressure_RR 16383 "SNA" ;
VAL_ 206 EPBMaster_Switch_1 3 "Not_Used_3" 2 "Down" 1 "Up" 0 "No_press" ;
VAL_ 206 RWU_Active_Master 1 "Active" 0 "Inactive" ;
VAL_ 206 SRU_Active_Master 1 "Active" 0 "Inactive" ;
VAL_ 206 LampCmd_EPBMaster_1 3 "Not_Used" 2 "On" 1 "Flash" 0 "Off" ;
VAL_ 206 BrakeForceNotEnoughWarning_EPBMa 1 "Warning" 0 "No_warning" ;
VAL_ 206 GradientHighWarning_EPBMaster_1 1 "Warning" 0 "No_warning" ;
VAL_ 206 EPBMasterDecelerationRequest 4095 "SNA" ;
VAL_ 206 StatusEPBMasterDecelerationReque 1 "Deceleration_Request" 0 "No_Request" ;
VAL_ 206 BrakeLightCtrlCmd_EPBMaster_1 1 "Illuminate" 0 "Not_illuminate" ;
VAL_ 206 WorkingSt_EPBMaster_1 7 "Not_Used_7" 6 "Not_Used_6" 5 "Not_Used_5" 4 "Applying" 3 "Unknown" 2 "Applied" 1 "Releasing" 0 "Released" ;
VAL_ 206 EPBMaster_TipInformation_1 3 "Not_Used_3" 2 "Lock_the_seat_belt_then_auto_release_is_activated" 1 "Press_the_brake_pedal_first_then_release_the_APB_button" 0 "No_tip" ;
VAL_ 206 AutoLockFunctionSt_EPBMaster_1 1 "On" 0 "Off" ;
VAL_ 206 BrakeOverHeat_EPBMaster_1 1 "Temp_too_high" 0 "Not_high" ;
VAL_ 206 ErrorSt_EPBMaster_1 7 "Not_Used_7" 6 "Not_Used_6" 5 "Not_Used_5" 4 "Test_mode" 3 "Both_Sides_Error" 2 "Right_Side_Error" 1 "Left_Side_Error" 0 "No_Error" ;
VAL_ 208 EPS1_SteeringWheelAngle 32767 "SNA" ;
VAL_ 208 EPS1_SteeringWheelAngleSign 1 "Right" 0 "Left" ;
VAL_ 208 EPS1_SteeringWheelSpeed 32767 "SNA" ;
VAL_ 208 EPS1_SteeringWheelSpeedSign 1 "Right" 0 "Left" ;
VAL_ 208 EPS1_SAS_St 3 "Angle signal invalid" 2 "Angle signal (Pinion angle) is ASILB level" 1 "Angel sensor is on De-Calibration status" 0 "Angle signal(Pinion angle)is ASILD level" ;
VAL_ 336 EPS_1_HandSteeringTorque 1023 "SNA" ;
VAL_ 336 EPS_1_HandSteeringTorqueSign 1 "Right_(Negative)" 0 "Left_(Positive)" ;
VAL_ 336 EPS_1_ErrorStatus 3 "Not_Used" 2 "Critical_Error(lose)" 1 "General_Error(Derate)" 0 "No_Error" ;
VAL_ 336 EPS_1_ModeChangeEnable 1 "Enable" 0 "Disable" ;
VAL_ 336 EPS_1_HandOffStatus 1 "Hands_On" 0 "Hands_Off" ;
VAL_ 336 EPS_1_HandOffValid 1 "Invalid" 0 "Valid" ;
VAL_ 336 EPS_1_LKAStatus 7 "Reserved" 6 "Reserved" 5 "Transit" 4 "Not_configured" 3 "Permanently_fail" 2 "Active" 1 "Available_for_control" 0 "Temporary_inhibit" ;
VAL_ 336 EPS_1_A_TASSensorStatus 1 "Error" 0 "No_error" ;
VAL_ 336 EPS_1_B_TASSensorStatus 1 "Error" 0 "No_error" ;
VAL_ 336 EPS_1_OverlayInputTorque 1023 "SNA" ;
VAL_ 336 EPS_1_OverlayInputTorqueSign 1 "Right_(Negative)" 0 "Left_(Positive)" ;
VAL_ 336 EPS_1_AbortFeedback 31 "Reserved" 30 "Reserved" 29 "Reserved" 28 "Reserved" 27 "Reserved" 26 "Reserved" 25 "Reserved" 24 "Reserved" 23 "Reserved" 22 "Reserved" 21 "Reserved" 20 "Reserved" 19 "Reserved" 18 "Reserved" 17 "Reserved" 16 "Reserved" 15 "Reserved" 14 "Reserved" 13 "Reserved" 12 "Reserved" 11 "Reserved" 10 "Reserved" 9 "Reserved" 8 "Reserved" 7 "Reserved" 6 "Reserved" 5 "Reserved" 4 "Reserved" 3 "Reserved" 2 "Irrecoverable_interruption" 1 "Recoverable_interruption" 0 "No_driving_interuption" ;
VAL_ 336 EPS_1_WorkingMode_DMS 15 "Invalid_value" 14 "Reserved" 13 "Reserved" 12 "Reserved" 11 "Reserved" 10 "Reserved" 9 "Reserved" 8 "Reserved" 7 "Reserved" 6 "Reserved" 5 "Reserved" 4 "Reserved" 3 "Reserved" 2 "Comfort" 1 "Sport" 0 "Auto" ;
VAL_ 337 EPS_1_SACCStatus 7 "Reserved" 6 "Reserved" 5 "Transit" 4 "Not_configured" 3 "Permanently_fail" 2 "Active" 1 "Available_for_control" 0 "Temporary_inhibit" ;
VAL_ 337 EPS_1_NOPStatus 7 "Reserved" 6 "Reserved" 5 "Transit" 4 "Not_configured" 3 "Permanently_fail" 2 "Active" 1 "Available_for_control" 0 "Temporary_inhibit" ;
VAL_ 337 EPS_1_NGPStatus 7 "Reserved" 6 "Reserved" 5 "Transit" 4 "Not_configured" 3 "Permanently_fail" 2 "Active" 1 "Available_for_control" 0 "Temporary_inhibit" ;
VAL_ 337 EPS_1_APAStatus 7 "Reserved" 6 "Reserved" 5 "Transit" 4 "Not_configured" 3 "Permanently_fail" 2 "Active" 1 "Available_for_control" 0 "Temporary_inhibit" ;
VAL_ 337 EPS_1_RPAStatus 7 "Reserved" 6 "Reserved" 5 "Transit" 4 "Not_configured" 3 "Permanently_fail" 2 "Active" 1 "Available_for_control" 0 "Temporary_inhibit" ;
VAL_ 337 EPS_1_AVPStatus 7 "Reserved" 6 "Reserved" 5 "Transit" 4 "Not_configured" 3 "Permanently_fail" 2 "Active" 1 "Available_for_control" 0 "Temporary_inhibit" ;
VAL_ 337 EPS_1_EMAStatus 7 "Reserved" 6 "Reserved" 5 "Transit" 4 "Not_configured" 3 "Permanently_fail" 2 "Active" 1 "Available_for_control" 0 "Temporary_inhibit" ;
VAL_ 337 EPS_1_DegradeLevel_HAD 15 "Critical_Error(lose)" 14 "Reserved" 13 "Reserved" 12 "Reserved" 11 "Reserved" 10 "Reserved" 9 "Reserved" 8 "DM8" 7 "DM7" 6 "DM6" 5 "DM5" 4 "DM4" 3 "DM3" 2 "DM2" 1 "DM1" 0 "No_Error" ;
VAL_ 337 EPS_1_PullingReminder 3 "Reserved" 2 "Reserved" 1 "Pulling" 0 "Normal" ;
VAL_ 337 EPS_1_AutoDrivingMode 15 "Reserved" 14 "Reserved" 13 "Reserved" 12 "Reserved" 11 "Reserved" 10 "L3Backup" 9 "NGP" 8 "AES" 7 "EMA" 6 "AVP" 5 "RPA" 4 "APA " 3 "NOP" 2 "SACC" 1 "LKA" 0 "Idle" ;
VAL_ 337 EPS_1_PullingTorque 1023 "SNA" ;
VAL_ 337 EPS_1_PullingTorqueSign 1 "Right_(Negative)" 0 "Left_(Positive)" ;
VAL_ 337 EPS_1_L3BackupStatus 7 "Reserved" 6 "Reserved" 5 "Transit" 4 "Not_configured" 3 "Permanently_fail" 2 "Active" 1 "Available_for_control" 0 "Temporary_inhibit" ;
VAL_ 195 TorqueReductionFast_TCS_FrontWhe 8191 "SNA" ;
VAL_ 195 TorqueIncrease_MSR_FrontWheel 16383 "SNA" ;
VAL_ 195 TorqueReductionFast_TCS_RearWhee 8191 "SNA" ;
VAL_ 195 TorqueIncrease_MSR_RearWheel 16383 "SNA" ;
VAL_ 195 ESC_RegenerationTorqueRequest 8191 "SNA" ;
VAL_ 195 ESC_RegenerationTorqueRequest_Q 3 "Normal_Passive" 2 "Faulty" 1 "Normal_Active" 0 "NotInitialized" ;
VAL_ 195 TorqReductionFastSt_TCS_FrontWhe 1 "Request" 0 "No_Request" ;
VAL_ 195 TorqueIncreaseSt_MSR_FrontWheel 1 "Request" 0 "No_Request" ;
VAL_ 195 TorqReductionFastSt_TCS_RearWhee 1 "Request" 0 "No_Request" ;
VAL_ 195 TorqueIncreaseSt_MSR_RearWheel 1 "Request" 0 "No_Request" ;
VAL_ 195 ESC_StatusRegenerationTorqueRequ 1 "Request" 0 "No_Request" ;
VAL_ 195 ESC_FrontBiasMax 127 "SNA" ;
VAL_ 195 ESC_RearBiasMax 127 "SNA" ;
VAL_ 306 WorkingSt_ESC 1 "On" 0 "Off" ;
VAL_ 306 ErrorSt_ESC 1 "Error" 0 "No_Error" ;
VAL_ 306 Intervention_ESC 1 "Intervention" 0 "No_Intervention" ;
VAL_ 306 ErrorSt_ABS 1 "Error" 0 "No_Error" ;
VAL_ 306 Intervention_ABS 1 "Intervention" 0 "No_Intervention" ;
VAL_ 306 ESC_Status_RollerBenchMode 1 "Active" 0 "Inactive" ;
VAL_ 306 Intervention_TCS 1 "Intervention" 0 "No_Intervention" ;
VAL_ 306 ErrorSt_EBD 1 "Error" 0 "No_error" ;
VAL_ 306 AvailableSt_CDP 1 "Available" 0 "Not_Available" ;
VAL_ 306 Intervention_CDP 1 "Intervention" 0 "No_intervention" ;
VAL_ 306 AvailableSt_HHC 1 "Available" 0 "Not_Available" ;
VAL_ 306 Intervention_HHC 1 "Intervention" 0 "No_intervention" ;
VAL_ 306 AvailableSt_HDC 1 "Available" 0 "Not_Available" ;
VAL_ 306 WorkingSt_HDC 3 "Error" 2 "Intervention" 1 "Standby" 0 "Off" ;
VAL_ 306 ErrorSt_AVH 1 "Error" 0 "No_Error" ;
VAL_ 306 WorkingSt_AVH 3 "Inactive" 2 "Intervention" 1 "Stand_By" 0 "Off" ;
VAL_ 306 AvailableSt_AEB 1 "Available" 0 "Not_Available" ;
VAL_ 306 Intervention_AEB 1 "Intervention" 0 "No_Intervention" ;
VAL_ 306 AvailableSt_ABP 1 "Available" 0 "Not_Available" ;
VAL_ 306 Intervention_ABP 1 "Intervention" 0 "No_Intervention" ;
VAL_ 306 AvailableSt_AWB 1 "Available" 0 "Not_Available" ;
VAL_ 306 Intervention_AWB 1 "Intervention" 0 "No_intervention" ;
VAL_ 306 AvailableSt_HBA 1 "Available" 0 "Not_Available" ;
VAL_ 306 Intervention_HBA 1 "Intervention" 0 "No_Intervention" ;
VAL_ 306 Intervention_EmergencyBrake 1 "Intervention" 0 "No_intervention" ;
VAL_ 306 VehicleStandstillSt_ESC 1 "The_vehicle_is_in_standstill." 0 "The_vehicle_is_not__in_standstill." ;
VAL_ 306 BrakeLightCtrlCmd_ESC 1 "Illuminate" 0 "Not_illuminate" ;
VAL_ 306 Intervention_BTCS_F 1 "Intervention" 0 "No_Intervention" ;
VAL_ 306 Intervention_BTCS_R 1 "Intervention" 0 "No_Intervention" ;
VAL_ 306 AvailableSt_MSR 1 "Available" 0 "Not_Available" ;
VAL_ 306 RoughRoadLevel 7 "Invalid_Value" 6 "level_6" 5 "level_5" 4 "level_4" 3 "level_3" 2 "level_2" 1 "level_1" 0 "Inactive" ;
VAL_ 306 BrakeHoldActive 1 "Active" 0 "Inactive" ;
VAL_ 306 ParkingRequestToEPB 3 "Not_Used" 2 "Lock_brake_request" 1 "Release_brake_request" 0 "No_request" ;
VAL_ 306 WorkingMode_ESC 15 "Invalid_value" 14 "Reserved" 13 "Reserved" 12 "Reserved" 11 "Reserved" 10 "Reserved" 9 "Reserved" 8 "Reserved" 7 "SportPlus" 6 "Sport" 5 "Sand" 4 "MUD_Ruts" 3 "Off_road" 2 "Snow" 1 "Eco" 0 "Auto" ;
VAL_ 306 ModeChangeEnable_ESC 1 "Enable" 0 "Disable" ;
VAL_ 306 WorkingSt_CST 3 "Error" 2 "Intervention" 1 "Standby" 0 "Off" ;
VAL_ 312 ESC_TorqueReq_VMC_1 131071 "SNA" ;
VAL_ 312 ESC_TorqueReqSt_VMC_1 3 "Not_Used" 2 "Not_Used" 1 "Request" 0 "No_Request" ;
VAL_ 312 ESC_TargetGearReq_VMC_1 7 "Invalid" 6 "Not_Used" 5 "Not_Used" 4 "Target_gear_D" 3 "Target_gear_N" 2 "Target_gear_R" 1 "Target_gear_P" 0 "No_Request" ;
VAL_ 312 ESC_TargetGearReqEnable_VMC_1 1 "Enable" 0 "Not enable" ;
VAL_ 312 ESC_SuspendStatus_L2 7 "Not_Used" 6 "Not_Used" 5 "Not_Used" 4 "RampOffByDriverBrake" 3 "SuspendByDriverPropulsion" 2 "Not_Used" 1 "Not_Used" 0 "No_Request" ;
VAL_ 312 ESC_EPBAvailableSt_L3 1 "Not Available" 0 "Available" ;
VAL_ 312 ESC_CommunicationSt_L3 1 "Valid" 0 "Invalid" ;
VAL_ 312 ESC_UsedChannel_L3 3 "HAD2Com1" 2 "HAD1Com2" 1 "HAD1Com1" 0 "NoChannel" ;
VAL_ 312 ESC_ControllerReleaseSt_L3 1 "Release" 0 "NotRelease" ;
VAL_ 312 ESC_SuspendStatusByDriver_L3 3 "Not_Used" 2 "SuspendByDriverPropulsion" 1 "SuspendByDriverBrake" 0 "No Suspend" ;
VAL_ 312 ESC_SuspendStatusByOther_L3 1 "SuspendByOtherBrake(CDP)" 0 "No Suspend" ;
VAL_ 312 ESC_VLC_Error_L12 3 "Not_Used" 2 "Available" 1 "NotAvailableBySituation" 0 "NotAvailable" ;
VAL_ 312 ESC_VLCSt 3 "Not_Used" 2 "Active_L3" 1 "Active_L12" 0 "Inactivce" ;
VAL_ 312 ESC_VMC_Error_L3 7 "Not_Used" 6 "Not_Used" 5 "Not_Used" 4 "Available" 3 "AvailableWithSituationIssue" 2 "AvailableWithFault" 1 "NotAvailableBySituation" 0 "NotAvailable" ;
VAL_ 312 ESC_AutoDriving_LC_Brakemode 3 "Not_Used" 2 "Emergency" 1 "Comfortable" 0 "Inactive" ;
VAL_ 312 ESC_AutoPark_LC_HPA_Avail 3 "Available" 2 "Not_Used" 1 "Test Pending" 0 "Not_Available" ;
VAL_ 312 ESC_AutoPark_LCSt 7 "Not Used" 6 "Active_AVP" 5 "Active_RPA" 4 "Active_APA" 3 "Active_HPA" 2 "Not_Used" 1 "Standby" 0 "Not Used" ;
VAL_ 312 ESC_AutoPark_LC_APA_Avail 3 "Available" 2 "Not_Used" 1 "Not_Used" 0 "Not_Available" ;
VAL_ 312 ESC_AutoPark_LC_RPA_Avail 3 "Available" 2 "Not_Used" 1 "Test Pending" 0 "Not_Available" ;
VAL_ 312 ESC_AutoPark_LC_AVP_Avail 3 "Available" 2 "Not_Used" 1 "Test Pending" 0 "Not_Available" ;
VAL_ 312 ESC_AutoPark_LCFailureSt 15 "Error" 14 "Not_Used_15" 13 "Not_Used_14" 12 "Not_Used_13" 11 "Not_Used_12" 10 "Not_Used_11" 9 "Not_Used_10" 8 "Speed_Too_High" 7 "Parking_Triggered_Without_Secure" 6 "Not_Used_7" 5 "Not_Used_6" 4 "Not_Used_5" 3 "Unexpected_EPB_Action" 2 "Unexpected_GearPosition" 1 "Vehicle_Blocked" 0 "No_Error" ;
VAL_ 312 ESC_AutoPark_LC_BrakeMode 3 "Not_Used" 2 "Emergency" 1 "Comfortable" 0 "Inactive" ;
VAL_ 312 ESC_HDCActiveForbidden 1 "Active" 0 "Inactive" ;
VAL_ 312 ESC_ESCOffForbidden 1 "Active" 0 "Inactive" ;
VAL_ 312 ESC_AVHActiveForbidden 1 "Active" 0 "Inactive" ;
VAL_ 312 ESC_ShutOffFinished 1 "Active" 0 "Inactive" ;
VAL_ 312 ESC_BrakePadelOverride 1 "Active" 0 "Inactive" ;
VAL_ 193 IBC_SimulatorPressure 1023 "SNA" ;
VAL_ 193 IBC_SimulatorPressureSt 1 "Valid" 0 "Invalid" ;
VAL_ 193 IBC_SystemStatus 7 "Not_Used_7" 6 "Not_Used_6" 5 "Not_Used_5" 4 "Hydraulic_Backup" 3 "BBF_C1/2BoostOnly" 2 "BBF_CircuitSperation" 1 "BBF_DegradedPedalFeel" 0 "BBF_FullSy" ;
VAL_ 193 IBC_PlungerPressure 1023 "SNA" ;
VAL_ 193 IBC_PlungerPressureSt 1 "Valid" 0 "Invalid" ;
VAL_ 193 IBC_BrakePedalStatus_Q 3 "Not_Used" 2 "Full" 1 "Fault" 0 "NotInitialized" ;
VAL_ 193 IBC_InputRodStroke 1023 "SNA" ;
VAL_ 193 IBC_InputRodStrokeSt 1 "Valid" 0 "Invalid" ;
VAL_ 193 IBC_BrakeFluidWarning 3 "Invalid" 2 "BrakeFluid_Electric_error" 1 "BrakeFluid_Empty" 0 "BrakeFluid_Normal" ;
VAL_ 193 IBC_BrakePedalStatus 3 "Error" 2 "Not_Used" 1 "Actuated" 0 "Not_Actuated" ;
VAL_ 193 TwoFootBrakeSt 1 "Two_foot_brake_occur" 0 "Normal" ;
VAL_ 193 DegradedBBFWarning 1 "Warning" 0 "No_warning" ;
VAL_ 193 IBC_MILInfo 1 "Active" 0 "Inactive" ;
VAL_ 193 FWAWarning 3 "Not_Used" 2 "brake_system_over_temperature_warning_level2" 1 "brake_system_over_temperature_warning_level1" 0 "No_Fault" ;
VAL_ 193 IBC_RearWheelAngleRequest 4095 "SNA" ;
VAL_ 193 IBC_RearWheelAngleRequestSt 1 "Valid" 0 "Invalid" ;
VAL_ 193 IBC_VDCActive 1 "Valid" 0 "Invalid" ;
VAL_ 554 LimphomeSt_FL 1 "On" 0 "Off" ;
VAL_ 554 PositionLightSt_FL 1 "On" 0 "Off" ;
VAL_ 554 DayRunningLightSt_FL 1 "On" 0 "Off" ;
VAL_ 554 FogLightSt_FL 1 "On" 0 "Off" ;
VAL_ 554 TurningSt_FL 1 "Active" 0 "Inactive" ;
VAL_ 554 TurningSt_LeftSide 1 "Active" 0 "Inactive" ;
VAL_ 554 ADSLightSt_FL 1 "On" 0 "Off" ;
VAL_ 554 CeremonyModeStatus_FL 7 "Reserved" 6 "Reserved" 5 "Mode 5" 4 "Mode 4" 3 "Mode 3" 2 "Mode 2" 1 "Mode 1" 0 "Off" ;
VAL_ 554 TurnLightFaultSt_LeftSide 1 "Fault" 0 "No fault" ;
VAL_ 554 HighBeamSt_FL 1 "On" 0 "Off" ;
VAL_ 554 FoglightFaultSt_FL 1 "Fault" 0 "No fault" ;
VAL_ 554 HighbeamFaultSt_FL 1 "Fault" 0 "No fault" ;
VAL_ 554 PositionLightFaultSt_FL 1 "Fault" 0 "No fault" ;
VAL_ 554 DayRunningLightFaultSt_FL 1 "Fault" 0 "No fault" ;
VAL_ 554 TurningLightFaultSt_FL 1 "Fault" 0 "No fault" ;
VAL_ 554 ADSLightFaultSt_FL 1 "Fault" 0 "No fault" ;
VAL_ 554 CornerLampSt_FL 1 "On" 0 "Off" ;
VAL_ 554 LampOTAMode_FL 1 "OTA Mode" 0 "Normal Mode" ;
VAL_ 554 CornerLampFaultSt_FL 1 "Fault" 0 "No fault" ;
VAL_ 554 ALS_Init_FL 3 "Failed" 2 "processing" 1 "Not Start" 0 "Over" ;
VAL_ 554 ALS_MotorFault_FL 7 "Reserved" 6 "Reserved" 5 "Short circuit" 4 "Open circuit" 3 "Overvoltage" 2 "Undervoltage" 1 "No-voltage" 0 "Normal" ;
VAL_ 502 LowBeamSt_FL 1 "On" 0 "Off" ;
VAL_ 502 LowbeamFaultSt_FL 1 "Fault" 0 "No fault" ;
VAL_ 810 LimphomeSt_FR 1 "On" 0 "Off" ;
VAL_ 810 PositionLightSt_FR 1 "On" 0 "Off" ;
VAL_ 810 DayRunningLightSt_FR 1 "On" 0 "Off" ;
VAL_ 810 FogLightSt_FR 1 "On" 0 "Off" ;
VAL_ 810 TurningSt_FR 1 "Active" 0 "Inactive" ;
VAL_ 810 TurningSt_RightSide 1 "Active" 0 "Inactive" ;
VAL_ 810 ADSLightSt_FR 1 "On" 0 "Off" ;
VAL_ 810 CeremonyModeStatus_FR 7 "Reserved" 6 "Reserved" 5 "Mode 5" 4 "Mode 4" 3 "Mode 3" 2 "Mode 2" 1 "Mode 1" 0 "Off" ;
VAL_ 810 TurnLightFaultSt_RightSide 1 "Fault" 0 "No fault" ;
VAL_ 810 HighBeamSt_FR 1 "On" 0 "Off" ;
VAL_ 810 FoglightFaultSt_FR 1 "Fault" 0 "No fault" ;
VAL_ 810 HighbeamFaultSt_FR 1 "Fault" 0 "No fault" ;
VAL_ 810 PositionLightFaultSt_FR 1 "Fault" 0 "No fault" ;
VAL_ 810 DayRunningLightFaultSt_FR 1 "Fault" 0 "No fault" ;
VAL_ 810 TurningLightFaultSt_FR 1 "Fault" 0 "No fault" ;
VAL_ 810 ADSLightFaultSt_FR 1 "Fault" 0 "No fault" ;
VAL_ 810 CornerLampSt_FR 1 "On" 0 "Off" ;
VAL_ 810 LampOTAMode_FR 1 "OTA Mode" 0 "Normal Mode" ;
VAL_ 810 CornerLampFaultSt_FR 1 "Fault" 0 "No fault" ;
VAL_ 810 ALS_Init_FR 3 "Failed" 2 "processing" 1 "Not Start" 0 "Over" ;
VAL_ 810 ALS_MotorFault_FR 7 "Reserved" 6 "Reserved" 5 "Short circuit" 4 "Open circuit" 3 "Overvoltage" 2 "Undervoltage" 1 "No-voltage" 0 "Normal" ;
VAL_ 501 LowBeamSt_FR 1 "On" 0 "Off" ;
VAL_ 501 LowbeamFaultSt_FR 1 "Fault" 0 "No fault" ;
